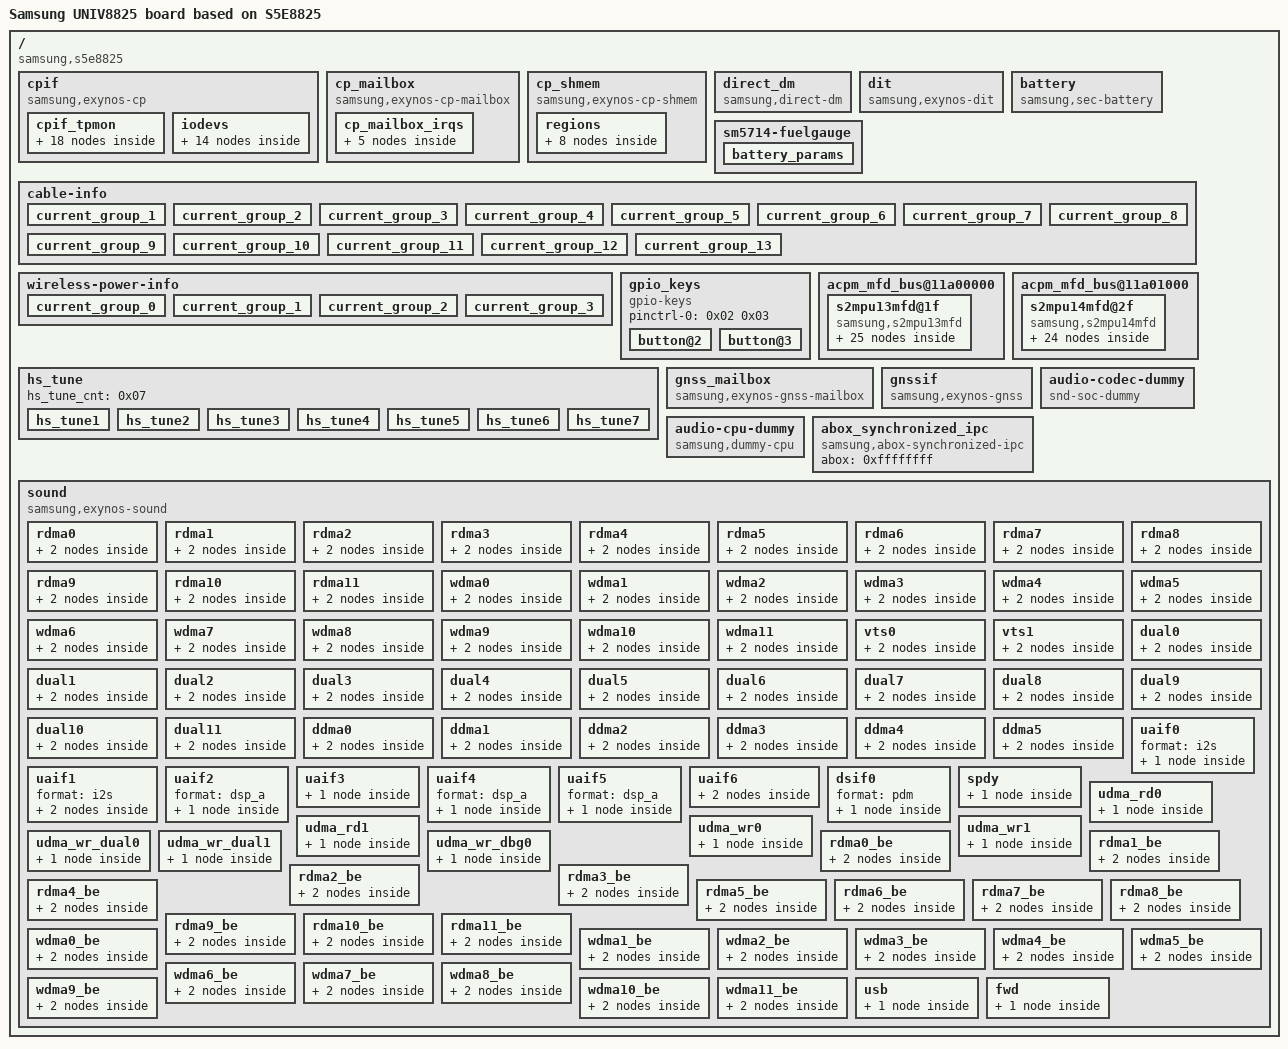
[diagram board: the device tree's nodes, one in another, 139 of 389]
/dts-v1/;

/ {
	compatible = "samsung,s5e8825\0samsung,UNIV8825";
	board_id = <0x01>;
	board_rev = <0x00>;

	fragment@modemif {
		target-path = "/";

		__overlay__ {
			#address-cells = <0x02>;
			#size-cells = <0x01>;

			cpif {
				compatible = "samsung,exynos-cp";
				status = "okay";
				interrupt-parent = <0xffffffff>;
				interrupts = <0x00 0x143 0x04 0x00 0x144 0x04>;
				interrupt-names = "RESET_REQ\0CP_ACTIVE";
				ap2cp_cfg_addr = <0x14020000>;
				mif,name = "s5308ap";
				mif,cp_num = <0x00>;
				mif,modem_type = <0x00>;
				mif,protocol = <0x01>;
				mif,ipc_version = <0x32>;
				mif,link_type = <0x00>;
				mif,link_name = "shmem";
				mif,link_attrs = <0x7c8>;
				mif,interrupt_types = <0x00>;
				mif,capability_check = <0x01>;
				mif,int_ap2cp_msg = <0x00>;
				mif,int_ap2cp_wakeup = <0x01>;
				mif,int_ap2cp_status = <0x02>;
				mif,int_ap2cp_active = <0x03>;
				mif,int_ap2cp_lcd_status = <0x04>;
				mif,int_ap2cp_llc_status = <0x05>;
				mif,int_ap2cp_uart_noti = <0x0f>;
				mif,irq_cp2ap_msg = <0x00>;
				mif,irq_cp2ap_status = <0x02>;
				mif,irq_cp2ap_active = <0x03>;
				mif,irq_cp2ap_llc_status = <0x05>;
				mif,irq_cp2ap_wakelock = <0x08>;
				mif,irq_cp2ap_ratmode = <0x09>;
				legacy_fmt_head_tail_offset = <0x10>;
				legacy_fmt_buffer_offset = <0x1000>;
				legacy_fmt_txq_size = <0x1000>;
				legacy_fmt_rxq_size = <0x1000>;
				legacy_raw_head_tail_offset = <0x20>;
				legacy_raw_buffer_offset = <0x3000>;
				legacy_raw_txq_size = <0x1fd000>;
				legacy_raw_rxq_size = <0x200000>;
				legacy_raw_rx_buffer_cached = <0x00>;
				legacy_raw_qos_head_tail_offset = <0x30>;
				legacy_raw_qos_buffer_offset = <0x400000>;
				legacy_raw_qos_txq_size = <0x100000>;
				legacy_raw_qos_rxq_size = <0x100000>;
				offset_cmsg_offset = <0x60>;
				offset_srinfo_offset = <0x64>;
				offset_clk_table_offset = <0x68>;
				offset_buff_desc_offset = <0x6c>;
				offset_capability_offset = <0x70>;
				cmsg_offset = <0xc0>;
				srinfo_offset = <0x300>;
				srinfo_size = <0x800>;
				clk_table_offset = <0x200>;
				buff_desc_offset = <0xc00>;
				capability_offset = <0xa0>;
				ap_capability_0 = <0x00>;
				ap_capability_1 = <0x00>;
				ap2cp_msg = <0x03 0x00>;
				cp2ap_msg = <0x03 0x04>;
				ap2cp_united_status = <0x03 0x08>;
				cp2ap_united_status = <0x03 0x0c>;
				ap2cp_llc_status = <0x03 0x10>;
				cp2ap_llc_status = <0x03 0x14>;
				ap2cp_kerneltime_sec = <0x03 0x38>;
				ap2cp_kerneltime_usec = <0x03 0x3c>;
				sbi_lcd_status_mask = <0x01>;
				sbi_lcd_status_pos = <0x1b>;
				sbi_crash_type_mask = <0x0f>;
				sbi_crash_type_pos = <0x17>;
				sbi_ext_backtrace_mask = <0x01>;
				sbi_ext_backtrace_pos = <0x11>;
				sbi_uart_noti_mask = <0x01>;
				sbi_uart_noti_pos = <0x10>;
				sbi_ds_det_mask = <0x03>;
				sbi_ds_det_pos = <0x0e>;
				sbi_sys_rev_mask = <0xff>;
				sbi_sys_rev_pos = <0x06>;
				sbi_pda_active_mask = <0x01>;
				sbi_pda_active_pos = <0x05>;
				sbi_ap_status_mask = <0x0f>;
				sbi_ap_status_pos = <0x01>;
				sbi_cp_rat_mode_mask = <0x3f>;
				sbi_cp_rat_mode_pos = <0x1a>;
				sbi_cp_evs_mode_mask = <0x01>;
				sbi_cp_evs_mode_pos = <0x07>;
				sbi_cp2ap_wakelock_mask = <0x01>;
				sbi_cp2ap_wakelock_pos = <0x06>;
				sbi_lte_active_mask = <0x01>;
				sbi_lte_active_pos = <0x05>;
				sbi_cp_status_mask = <0x0f>;
				sbi_cp_status_pos = <0x01>;
				sbi_ap_llc_return_mask = <0x0f>;
				sbi_ap_llc_return_pos = <0x09>;
				sbi_ap_llc_alloc_mask = <0x01>;
				sbi_ap_llc_alloc_pos = <0x08>;
				sbi_ap_llc_way_mask = <0xff>;
				sbi_ap_llc_way_pos = <0x00>;
				sbi_cp_llc_return_mask = <0x0f>;
				sbi_cp_llc_return_pos = <0x09>;
				sbi_cp_llc_alloc_mask = <0x01>;
				sbi_cp_llc_alloc_pos = <0x08>;
				sbi_cp_llc_way_mask = <0xff>;
				sbi_cp_llc_way_pos = <0x00>;
				cp_btl_node_name = "ramdump_memshare";
				pktproc_use_36bit_addr = <0x00>;
				pktproc_cp_base = <0x00 0x50800000>;
				pktproc_dl_support = <0x01>;
				pktproc_dl_version = <0x02>;
				pktproc_dl_info_rgn_offset = <0x00>;
				pktproc_dl_info_rgn_size = <0x1000>;
				pktproc_dl_desc_rgn_offset = <0x2000>;
				pktproc_dl_desc_rgn_size = <0xfe000>;
				pktproc_dl_buff_rgn_offset = <0x200000>;
				pktproc_dl_buff_rgn_size = <0x1a00000>;
				pktproc_dl_info_rgn_cached = <0x00>;
				pktproc_dl_desc_rgn_cached = <0x00>;
				pktproc_dl_buff_rgn_cached = <0x00>;
				pktproc_dl_desc_mode = <0x01>;
				pktproc_dl_num_queue = <0x01>;
				pktproc_dl_use_exclusive_irq = <0x01>;
				pktproc_dl_exclusive_irq_idx = <0x01 0x02 0x03 0x04>;
				pktproc_dl_use_netrx_mng = <0x00>;
				pktproc_dl_netrx_capacity = <0x1388>;
				pktproc_dl_use_napi = <0x01>;
				pktproc_dl_use_hw_iocc = <0x00>;
				pktproc_dl_max_packet_size = <0xc00>;
				pktproc_dl_use_dedicated_baaw = <0x00>;
				pktproc_ul_support = <0x01>;
				pktproc_ul_info_rgn_offset = <0x1000>;
				pktproc_ul_info_rgn_size = <0x1000>;
				pktproc_ul_desc_rgn_offset = <0x100000>;
				pktproc_ul_desc_rgn_size = <0x100000>;
				pktproc_ul_buff_rgn_offset = <0x1c00000>;
				pktproc_ul_buff_rgn_size = <0x400000>;
				pktproc_ul_padding_required = <0x01>;
				pktproc_ul_num_queue = <0x02>;
				pktproc_ul_max_packet_size = <0x800>;
				pktproc_ul_hiprio_ack_only = <0x01>;
				pktproc_ul_info_rgn_cached = <0x00>;
				pktproc_ul_desc_rgn_cached = <0x00>;
				pktproc_ul_buff_rgn_cached = <0x00>;
				pktproc_ul_use_hw_iocc = <0x00>;
				devfreq_use_dfs_max_freq = <0x00>;

				cpif_tpmon {
					trigger_msec_min = <0x1f4>;
					trigger_msec_max = <0x5dc>;
					monitor_interval_msec = <0x3e8>;
					monitor_hold_msec = <0xbb8>;
					monitor_stop_mbps = <0x0f>;
					boost_hold_msec = <0x1770>;

					tpmon_rps {
						boost_name = "RPS";
						target = <0x00>;
						extra_idx = <0x00>;
						level = <0x13 0x80>;

						boost0 {
							enable = <0x01>;
							measure = <0x00>;
							proto = <0x00>;
							boost_threshold = <0x12c>;
							unboost_threshold_mbps = <0x78>;
						};
					};

					tpmon_gro_flush_time {
						boost_name = "GRO";
						target = <0x01>;
						extra_idx = <0x00>;
						level = <0x1e8480 0x1e8480 0x1e8480>;

						boost0 {
							enable = <0x01>;
							measure = <0x00>;
							proto = <0x00>;
							boost_threshold = <0x64 0xc8>;
							unboost_threshold_mbps = <0x32 0x78>;
						};
					};

					tpmon_mif {
						boost_name = "MIF";
						target = <0x02>;
						extra_idx = <0x00>;
						level = <0x00 0xf78f0>;

						boost0 {
							enable = <0x01>;
							measure = <0x00>;
							proto = <0x01>;
							boost_threshold = <0x2bc>;
							unboost_threshold_mbps = <0x12c>;
						};
					};

					tpmon_cpu_cl0 {
						boost_name = "CL0";
						target = <0x09>;
						extra_idx = <0x00>;
						level = <0x00 0x104410 0x123fe0>;

						boost0 {
							enable = <0x00>;
							measure = <0x00>;
							proto = <0x01>;
							boost_threshold = <0x64 0x12c>;
							unboost_threshold_mbps = <0x28 0x78>;
						};
					};

					tpmon_cpu_cl1 {
						boost_name = "CL1";
						target = <0x0a>;
						extra_idx = <0x06>;
						level = <0x00 0xb8150 0x1174c0 0x1702a0>;

						boost0 {
							enable = <0x00>;
							measure = <0x00>;
							proto = <0x01>;
							boost_threshold = <0x1f4 0x2bc 0x5dc>;
							unboost_threshold_mbps = <0xc8 0x12c 0x258>;
						};
					};

					tpmon_irq_dit {
						boost_name = "IRQ_DIT";
						target = <0x06>;
						extra_idx = <0x00>;
						level = <0x05 0x06>;

						boost0 {
							enable = <0x01>;
							measure = <0x00>;
							proto = <0x00>;
							boost_threshold = <0x7d0>;
							unboost_threshold_mbps = <0x320>;
						};

						boost1 {
							enable = <0x01>;
							measure = <0x02>;
							proto = <0x00>;
							boost_threshold = <0x1770>;
							unboost_threshold_mbps = <0x7d0>;
						};

						boost2 {
							enable = <0x01>;
							measure = <0x03>;
							proto = <0x00>;
							boost_threshold = <0x1b58>;
							unboost_threshold_mbps = <0x7d0>;
						};
					};

					tpmon_int_freq {
						boost_name = "INT";
						target = <0x07>;
						extra_idx = <0x00>;
						level = <0x00 0x61a80 0x82208>;

						boost0 {
							enable = <0x01>;
							measure = <0x00>;
							proto = <0x00>;
							boost_threshold = <0x7d0 0xbb8>;
							unboost_threshold_mbps = <0x320 0x4b0>;
						};
					};

					tpmon_bts_dit {
						boost_name = "BTS_DIT";
						target = <0x08>;
						extra_idx = <0x00>;
						level = <0x00 0x01>;

						boost0 {
							enable = <0x01>;
							measure = <0x03>;
							proto = <0x00>;
							boost_threshold = <0xfa0>;
							unboost_threshold_mbps = <0x12c>;
						};
					};
				};

				iodevs {

					io_device_0 {
						iod,name = "umts_ipc";
						iod,ch = <0xf5>;
						iod,format = <0x00>;
						iod,io_type = <0x01>;
						iod,link_type = <0x00>;
						iod,attrs = <0x2000>;
						iod,ch_count = <0x02>;
					};

					io_device_1 {
						iod,name = "umts_rfs0";
						iod,ch = <0x29>;
						iod,format = <0x01>;
						iod,io_type = <0x01>;
						iod,link_type = <0x00>;
						iod,attrs = <0x00>;
					};

					io_device_2 {
						iod,name = "umts_router";
						iod,ch = <0x15>;
						iod,format = <0x01>;
						iod,io_type = <0x01>;
						iod,link_type = <0x00>;
						iod,attrs = <0x00>;
					};

					io_device_3 {
						iod,name = "umts_dm0";
						iod,ch = <0x51>;
						iod,format = <0x01>;
						iod,io_type = <0x01>;
						iod,link_type = <0x00>;
						iod,attrs = <0x00>;
					};

					io_device_4 {
						iod,name = "umts_loopback";
						iod,ch = <0x52>;
						iod,format = <0x01>;
						iod,io_type = <0x01>;
						iod,link_type = <0x00>;
						iod,attrs = <0x00>;
					};

					io_device_5 {
						iod,name = "rmnet";
						iod,ch = <0x01>;
						iod,format = <0x01>;
						iod,io_type = <0x02>;
						iod,link_type = <0x00>;
						iod,attrs = <0x2000>;
						iod,ch_count = <0x08>;
					};

					io_device_6 {
						iod,name = "multipdp";
						iod,ch = <0x00>;
						iod,format = <0x03>;
						iod,io_type = <0x03>;
						iod,link_type = <0x00>;
						iod,attrs = <0x00>;
					};

					io_device_7 {
						iod,name = "umts_boot0";
						iod,ch = <0xf1>;
						iod,format = <0x04>;
						iod,io_type = <0x00>;
						iod,link_type = <0x00>;
						iod,attrs = <0x200>;
					};

					io_device_8 {
						iod,name = "umts_rcs0";
						iod,ch = <0x5b>;
						iod,format = <0x00>;
						iod,io_type = <0x01>;
						iod,link_type = <0x00>;
						iod,attrs = <0x00>;
					};

					io_device_9 {
						iod,name = "umts_rcs1";
						iod,ch = <0x5c>;
						iod,format = <0x01>;
						iod,io_type = <0x01>;
						iod,link_type = <0x00>;
						iod,attrs = <0x00>;
					};

					io_device_10 {
						iod,name = "umts_wfc0";
						iod,ch = <0x5d>;
						iod,format = <0x00>;
						iod,io_type = <0x01>;
						iod,link_type = <0x00>;
						iod,attrs = <0x00>;
					};

					io_device_11 {
						iod,name = "umts_wfc1";
						iod,ch = <0x5e>;
						iod,format = <0x01>;
						iod,io_type = <0x01>;
						iod,link_type = <0x00>;
						iod,attrs = <0x00>;
					};

					io_device_12 {
						iod,name = "umts_embms";
						iod,ch = <0x1e>;
						iod,format = <0x01>;
						iod,io_type = <0x02>;
						iod,link_type = <0x00>;
						iod,attrs = <0x2000>;
						iod,ch_count = <0x02>;
					};

					io_device_13 {
						iod,name = "umts_atc0";
						iod,ch = <0x17>;
						iod,format = <0x01>;
						iod,io_type = <0x01>;
						iod,link_type = <0x00>;
						iod,attrs = <0x00>;
					};
				};
			};

			cp_mailbox {
				compatible = "samsung,exynos-cp-mailbox";
				reg = <0x00 0x11920000 0x200>;
				num_shared_reg = <0x0a>;
				shared_reg_offset = <0x100>;
				use_sw_reset_reg = <0x00>;
				interrupt-parent = <0xffffffff>;
				interrupts = <0x00 0x1f 0x04 0x00 0x20 0x04 0x00 0x21 0x04 0x00 0x22 0x04 0x00 0x23 0x04>;

				cp_mailbox_irqs {

					cp_irq_0 {
						cp_irq,enable = <0x01>;
						cp_irq,idx = <0x00>;
						cp_irq,name = "cp_mbox_irq_0";
						cp_irq,sfr = <0x00 0x10 0x14 0x00>;
						cp_irq,affinity = <0x02>;
					};

					cp_irq_1 {
						cp_irq,enable = <0x01>;
						cp_irq,idx = <0x01>;
						cp_irq,name = "cp_mbox_irq_1";
						cp_irq,sfr = <0x28 0x00 0x14 0x00>;
						cp_irq,affinity = <0x03>;
					};

					cp_irq_2 {
						cp_irq,enable = <0x00>;
						cp_irq,idx = <0x02>;
						cp_irq,name = "cp_mbox_irq_2";
						cp_irq,sfr = <0x3c 0x00 0x14 0x00>;
						cp_irq,affinity = <0x02>;
					};

					cp_irq_3 {
						cp_irq,enable = <0x00>;
						cp_irq,idx = <0x03>;
						cp_irq,name = "cp_mbox_irq_3";
						cp_irq,sfr = <0x50 0x00 0x14 0x00>;
						cp_irq,affinity = <0x01>;
					};

					cp_irq_4 {
						cp_irq,enable = <0x01>;
						cp_irq,idx = <0x04>;
						cp_irq,name = "cp_mbox_irq_4";
						cp_irq,sfr = <0x64 0x00 0x14 0x00>;
						cp_irq,affinity = <0x02>;
					};
				};
			};

			cp_shmem {
				compatible = "samsung,exynos-cp-shmem";
				memory-region = <0xffffffff 0x01>;
				cp_num = <0x00>;
				use_mem_map_on_cp = <0x01>;

				regions {

					cp {
						region,name = "CP";
						region,index = <0x00>;
						region,rmem = <0x00>;
						region,offset = <0x00>;
						region,size = <0xf800000>;
						region,cached = <0x00>;
					};

					vss {
						region,name = "VSS";
						region,index = <0x01>;
						region,rmem = <0x00>;
						region,offset = <0xf800000>;
						region,size = <0x800000>;
						region,cached = <0x00>;
					};

					ipc {
						region,name = "IPC";
						region,index = <0x03>;
						region,rmem = <0x01>;
						region,offset = <0x00>;
						region,size = <0x800000>;
						region,cached = <0x00>;
					};

					pktproc {
						region,name = "PKTPROC";
						region,index = <0x07>;
						region,rmem = <0x01>;
						region,offset = <0x800000>;
						region,size = <0x1c00000>;
					};

					pktproc_ul {
						region,name = "PKTPROC_UL";
						region,index = <0x08>;
						region,rmem = <0x01>;
						region,offset = <0x2400000>;
						region,size = <0x400000>;
						region,cached = <0x00>;
					};

					l2b {
						region,name = "L2B";
						region,index = <0x02>;
						region,rmem = <0x01>;
						region,offset = <0x2800000>;
						region,size = <0xf00000>;
					};

					ddm {
						region,name = "DDM";
						region,index = <0x0c>;
						region,rmem = <0x01>;
						region,offset = <0x3700000>;
						region,size = <0x400000>;
					};

					btl {
						region,name = "BTL";
						region,index = <0x05>;
						region,rmem = <0x01>;
						region,offset = <0x3b00000>;
						region,size = <0x2000000>;
						region,cached = <0x00>;
					};
				};
			};

			direct_dm {
				compatible = "samsung,direct-dm";
				version = <0x01>;
				shm_rgn_index = <0x0c>;
				hw_iocc = <0x00>;
				info_desc_rgn_cached = <0x00>;
				buff_rgn_cached = <0x00>;
				info_rgn_offset = <0x00>;
				info_rgn_size = <0x100>;
				desc_rgn_offset = <0x100>;
				desc_rgn_size = <0x7f00>;
				buff_rgn_offset = <0x8000>;
				max_packet_size = <0x8000>;
				usb_req_num = <0x80>;
				irq_index = <0x04>;
				use_rx_task = <0x00>;
				use_rx_timer = <0x01>;
				rx_timer_period_msec = <0x3e8>;
			};
		};
	};

	fragment@0 {
		target = <0xffffffff>;

		__overlay__ {
			#address-cells = <0x02>;
			#size-cells = <0x01>;

			cp_rmem1 {
				compatible = "exynos,modem_if";
				reg = <0x08 0x90000000 0x5b00000>;
				rmem_index = <0x01>;
				phandle = <0x01>;
			};
		};
	};

	fragment@dit {
		target-path = "/";

		__overlay__ {
			#address-cells = <0x02>;
			#size-cells = <0x01>;

			dit {
				compatible = "samsung,exynos-dit";
				status = "okay";
				interrupt-parent = <0xffffffff>;
				interrupts = <0x00 0x1dd 0x04 0x00 0x1dc 0x04 0x00 0x1db 0x04 0x00 0x1de 0x04 0x00 0x1df 0x04>;
				interrupt-names = "DIT-RxDst0\0DIT-RxDst1\0DIT-RxDst2\0DIT-Tx\0DIT-Err";
				reg = <0x00 0x12950000 0x10000>;
				reg-names = "dit";
				dit_hw_capabilities = <0x00>;
				dit_use_tx = <0x01>;
				dit_use_rx = <0x01>;
				dit_use_clat = <0x00>;
				dit_use_recycling = <0x01>;
				dit_hal_support = <0x00>;
				dit_hal_enqueue_rx = <0x00>;
				dit_rx_extra_desc_ring_len = <0x800>;
				dit_irq_affinity = <0x02>;
			};
		};
	};

	fragment@battery {
		target-path = "/";

		__overlay__ {

			battery {
				status = "okay";
				compatible = "samsung,sec-battery";
				pinctrl-names = "default";
				battery,vendor = "Battery";
				battery,charger_name = "sm5714-charger";
				battery,fuelgauge_name = "sm5714-fuelgauge";
				battery,technology = <0x02>;
				battery,fgsrc_switch_name = "sm5714-fuelgauge";
				battery,batt_data_version = <0x03>;
				battery,chip_vendor = "LSI";
				battery,temp_adc_type = <0x01>;
				battery,temp_check_type = <0x03>;
				battery,usb_temp_check_type = <0x03>;
				battery,chg_temp_check_type = <0x03>;
				battery,wpc_temp_check_type = <0x03>;
				battery,dchg_temp_check_type = <0x03>;
				battery,thermal_source = <0x02>;
				battery,usb_thermal_source = <0x02>;
				battery,chg_thermal_source = <0x02>;
				battery,wpc_thermal_source = <0x02>;
				battery,dchg_thermal_source = <0x03>;
				battery,polling_time = <0x0a 0x1e 0x1e 0x1e 0xe10>;
				battery,temp_table_adc = <0x137 0x168 0x1a0 0x1e3 0x232 0x28f 0x2fb 0x379 0x409 0x48a 0x53c 0x603 0x6da 0x7ba 0x8ab 0x99b 0xa8a 0xb6a 0xc33 0xce8 0xd89 0xe04 0xe5f>;
				battery,temp_table_data = <0x384 0x352 0x320 0x2ee 0x2bc 0x28a 0x258 0x226 0x1f4 0x1c2 0x190 0x15e 0x12c 0xfa 0xc8 0x96 0x64 0x32 0x00 0xffffffce 0xffffff9c 0xffffff6a 0xffffff38>;
				battery,usb_temp_table_adc = <0x10c 0x146 0x180 0x1c5 0x214 0x270 0x2dd 0x35b 0x3e9 0x489 0x54c 0x616 0x6ee 0x7d0 0x8bb 0x9a6 0xa84 0xb61 0xc1c 0xcce 0xd67 0xdd3 0xe51>;
				battery,usb_temp_table_data = <0x384 0x352 0x320 0x2ee 0x2bc 0x28a 0x258 0x226 0x1f4 0x1c2 0x190 0x15e 0x12c 0xfa 0xc8 0x96 0x64 0x32 0x00 0xffffffce 0xffffff9c 0xffffff6a 0xffffff38>;
				battery,chg_temp_table_adc = <0xdd 0x114 0x14b 0x18e 0x1da 0x234 0x29b 0x31a 0x3a7 0x448 0x505 0x5d1 0x6af 0x799 0x889 0x97c 0xa69 0xb4f 0xc1f 0xcdb 0xd76 0xdf0 0xe75>;
				battery,chg_temp_table_data = <0x384 0x352 0x320 0x2ee 0x2bc 0x28a 0x258 0x226 0x1f4 0x1c2 0x190 0x15e 0x12c 0xfa 0xc8 0x96 0x64 0x32 0x00 0xffffffce 0xffffff9c 0xffffff6a 0xffffff38>;
				battery,wpc_temp_table_adc = <0x137 0x168 0x1a0 0x1e3 0x232 0x28f 0x2fb 0x379 0x409 0x48a 0x53c 0x603 0x6da 0x7ba 0x8ab 0x99b 0xa8a 0xb6a 0xc33 0xce8 0xd89 0xe04 0xe5f>;
				battery,wpc_temp_table_data = <0x384 0x352 0x320 0x2ee 0x2bc 0x28a 0x258 0x226 0x1f4 0x1c2 0x190 0x15e 0x12c 0xfa 0xc8 0x96 0x64 0x32 0x00 0xffffffce 0xffffff9c 0xffffff6a 0xffffff38>;
				battery,dchg_temp_table_adc = <0x15c3c 0x1b7e0 0x21384 0x2817c 0x301c8 0x39d92 0x454da 0x527a0 0x61f0e 0x731fa 0x86064 0x9c5ca 0xb3d84 0xcd9e6 0xe7648 0x1024fe 0x11c160 0x134b6e 0x14b9fe 0x15fabc 0x170da8 0x17f2c2 0x18b334>;
				battery,dchg_temp_table_data = <0x384 0x352 0x320 0x2ee 0x2bc 0x28a 0x258 0x226 0x1f4 0x1c2 0x190 0x15e 0x12c 0xfa 0xc8 0x96 0x64 0x32 0x00 0xffffffce 0xffffff9c 0xffffff6a 0xffffff38>;
				battery,wireless_cc_cv = <0x55>;
				battery,wpc_cc_cv_vout = <0x157c>;
				battery,wpc_cv_call_vout = <0x1388>;
				battery,wpc_cc_call_vout = <0x1388>;
				battery,hv_vout_wa = <0x41>;
				battery,adc_check_count = <0x05>;
				battery,cable_check_type = <0x04>;
				battery,cable_source_type = <0x01>;
				battery,polling_type = <0x01>;
				battery,monitor_initial_count = <0x00>;
				battery,battery_check_type = <0x00>;
				battery,check_count = <0x00>;
				battery,check_adc_max = <0x5a0>;
				battery,check_adc_min = <0x00>;
				battery,ovp_uvlo_check_type = <0x03>;
				battery,temp_check_count = <0x01>;
				battery,overheatlimit_threshold = <0x2bc>;
				battery,overheatlimit_recovery = <0x2a8>;
				battery,wire_warm_overheat_thresh = <0x1f4>;
				battery,wire_normal_warm_thresh = <0x19a>;
				battery,wire_cool1_normal_thresh = <0xb4>;
				battery,wire_cool2_cool1_thresh = <0x96>;
				battery,wire_cool3_cool2_thresh = <0x32>;
				battery,wire_cold_cool3_thresh = <0x00>;
				battery,wireless_warm_overheat_thresh = <0x1c2>;
				battery,wireless_normal_warm_thresh = <0x19a>;
				battery,wireless_cool1_normal_thresh = <0xb4>;
				battery,wireless_cool2_cool1_thresh = <0x96>;
				battery,wireless_cool3_cool2_thresh = <0x32>;
				battery,wireless_cold_cool3_thresh = <0x00>;
				battery,wire_warm_current = <0x625>;
				battery,wire_cool1_current = <0xc4a>;
				battery,wire_cool2_current = <0x418>;
				battery,wire_cool3_current = <0x1b5>;
				battery,wireless_warm_current = <0x418>;
				battery,wireless_cool1_current = <0xc4a>;
				battery,wireless_cool2_current = <0x418>;
				battery,wireless_cool3_current = <0x1b5>;
				battery,tx_high_threshold = <0x1c2>;
				battery,tx_high_recovery = <0x190>;
				battery,tx_low_threshold = <0x00>;
				battery,tx_low_recovery = <0x32>;
				battery,full_check_type = <0x02>;
				battery,full_check_type_2nd = <0x02>;
				battery,full_check_count = <0x01>;
				battery,chg_gpio_full_check = <0x00>;
				battery,chg_polarity_full_check = <0x01>;
				battery,chg_high_temp = <0x1d6>;
				battery,chg_high_temp_recovery = <0x1c2>;
				battery,dchg_high_temp = <0x208>;
				battery,dchg_high_temp_recovery = <0x1cc>;
				battery,dchg_high_batt_temp = <0x190>;
				battery,dchg_high_batt_temp_recovery = <0x17c>;
				battery,chg_input_limit_current = <0x3e8>;
				battery,chg_charging_limit_current = <0x76c>;
				battery,dchg_input_limit_current = <0x3e8>;
				battery,dchg_charging_limit_current = <0x7d0>;
				battery,charging_limit_by_tx_check = <0x01>;
				battery,charging_limit_current_by_tx = <0x4b0>;
				battery,wpc_temp_control_source = <0x01>;
				battery,wpc_high_temp = <0x190>;
				battery,wpc_high_temp_recovery = <0x17c>;
				battery,wpc_input_limit_current = <0x258>;
				battery,wpc_charging_limit_current = <0x3e8>;
				battery,wpc_temp_lcd_on_control_source = <0x01>;
				battery,wpc_lcd_on_high_temp = <0x190>;
				battery,wpc_lcd_on_high_temp_rec = <0x17c>;
				battery,wpc_lcd_on_input_limit_current = <0x1c2>;
				battery,wpc_store_high_temp = <0x168>;
				battery,wpc_store_high_temp_recovery = <0x154>;
				battery,wpc_store_lcd_on_high_temp = <0x168>;
				battery,wpc_store_lcd_on_high_temp_rec = <0x12c>;
				battery,wpc_store_lcd_on_charging_limit_current = <0x190>;
				battery,sleep_mode_limit_current = <0x320>;
				battery,wc_full_input_limit_current = <0x64>;
				battery,mix_high_temp = <0x1a4>;
				battery,mix_high_chg_temp = <0x1f4>;
				battery,mix_high_dc_temp = <0x244>;
				battery,mix_high_temp_recovery = <0x186>;
				battery,full_condition_type = <0x09>;
				battery,full_condition_soc = <0x5d>;
				battery,full_condition_vcell = <0x10ea>;
				battery,recharge_check_count = <0x01>;
				battery,recharge_condition_type = <0x04>;
				battery,recharge_condition_soc = <0x62>;
				battery,recharge_condition_vcell = <0x10d6>;
				battery,charging_total_time = <0x3840>;
				battery,hv_charging_total_time = <0x2a30>;
				battery,normal_charging_total_time = <0x4650>;
				battery,usb_charging_total_time = <0x8ca0>;
				battery,recharging_total_time = <0x1518>;
				battery,charging_reset_time = <0x00>;
				battery,chg_float_voltage = <0x111c>;
				battery,chg_ocp_current = <0x1838>;
				battery,chg_ocp_dtc = <0x64>;
				battery,swelling_drop_float_voltage = <0x1036>;
				battery,swelling_high_rechg_voltage = <0xfa0>;
				battery,swelling_low_rechg_voltage = <0xfa0>;
				battery,wa_float_voltage = <0xfd2>;
				battery,siop_event_check_type = <0x01>;
				battery,siop_call_cv_current = <0x12c>;
				battery,siop_call_cc_current = <0x12c>;
				battery,siop_input_limit_current = <0x4b0>;
				battery,siop_charging_limit_current = <0x3e8>;
				battery,siop_hv_input_limit_current = <0x2bc>;
				battery,siop_hv_charging_limit_current = <0x3e8>;
				battery,siop_apdo_input_limit_current = <0x4b0>;
				battery,siop_apdo_charging_limit_current = <0x7d0>;
				battery,siop_wireless_input_limit_current = <0x258>;
				battery,siop_wireless_charging_limit_current = <0x352>;
				battery,siop_hv_wireless_input_limit_current = <0x2bc>;
				battery,siop_hv_wireless_charging_limit_current = <0x352>;
				battery,siop_store_hv_wireless_input_limit_current = <0x1c2>;
				battery,store_mode_buckoff;
				battery,ttf_hv_charge_current = <0xbb8>;
				battery,ttf_hv_wireless_charge_current = <0x5dc>;
				battery,ttf_wireless_charge_current = <0x384>;
				battery,ttf_dc25_charge_current = <0x1068>;
				battery,ttf_dc45_charge_current = <0x1770>;
				battery,rp_current_rp1 = <0x1f4>;
				battery,rp_current_rp2 = <0x5dc>;
				battery,rp_current_rp3 = <0xbb8>;
				battery,rp_current_rdu_rp3 = <0x834>;
				battery,rp_current_abnormal_rp3 = <0x708>;
				battery,pd_charging_charge_power = <0x3a98>;
				battery,max_charging_current = <0xc4e>;
				battery,max_charging_charge_power = <0x61a8>;
				battery,battery_full_capacity = <0x1194>;
				battery,age_data = <0x00 0x111c 0x10d6 0x10ea 0x5d 0x12c 0x1108 0x10c2 0x10d6 0x5c 0x190 0x10f4 0x10ae 0x10c2 0x5b 0x2bc 0x10e0 0x109a 0x10ae 0x5a 0x3e8 0x10ae 0x1068 0x107c 0x59>;
				battery,health_condition = <0x384 0x4b 0x4b0 0x41 0x5dc 0x37>;
				battery,step_charging_type = <0x00>;
				battery,dc_step_chg_type = <0x6b>;
				battery,dc_step_chg_charge_power = <0x55f0>;
				battery,dc_step_chg_step = <0x03>;
				battery,dc_step_chg_step_2nd = <0x00>;
				battery,dc_step_chg_cond_vol = <0x101d 0x109a 0x111c>;
				battery,dc_step_chg_cond_iin = <0x7ee 0x721 0x00>;
				battery,dc_step_chg_val_vfloat = <0x101d 0x109a 0x111c>;
				battery,dc_step_chg_val_iout = <0x14aa 0xffa 0xe56>;
				battery,dc_step_chg_cond_soc = <0x14 0x32 0x64 0x14 0x32 0x64 0x14 0x32 0x64 0x14 0x32 0x64 0x14 0x32 0x64>;
				battery,pre_afc_input_current = <0x1f4>;
				battery,pre_afc_work_delay = <0x2710>;
				battery,prepare_ta_delay = <0x00>;
				battery,max_input_voltage = <0x2328>;
				battery,max_input_current = <0xbb8>;
				battery,enable_sysovlo_irq;
				battery,enable_noise_wa;
				battery,dis_auto_shipmode_temp_ctrl;
				battery,standard_curr = <0xc4e>;
				battery,expired_time = <0x2a30>;
				battery,recharging_expired_time = <0x1518>;
				battery,cisd_max_voltage_thr = <0x114e>;
				battery,cisd_alg_index = <0x08>;
				battery,ignore_cisd_index = <0x00 0x280>;
				battery,ignore_cisd_index_d = <0x00 0x50>;
				battery,tx_stop_capacity = <0x1e>;
				battery,tx_minduty_default = <0x14>;
				battery,tx_minduty_5V = <0x32>;
				battery,tx_uno_iout = <0x5dc>;
				battery,tx_mfc_iout_gear = <0x5dc>;
				battery,tx_mfc_iout_phone = <0x44c>;
				battery,tx_mfc_iout_phone_5v = <0x12c>;
				battery,tx_mfc_iout_lcd_on = <0x384>;
				#io-channel-cells = <0x05>;
				phandle = <0x15>;
			};

			sm5714-fuelgauge {
				status = "okay";
				fuelgauge,fuel_alert_soc = <0x01>;
				fuelgauge,capacity_max = <0x3e8>;
				fuelgauge,capacity_max_margin = <0x12c>;
				fuelgauge,capacity_min = <0x00>;
				fuelgauge,capacity_calculation_type = <0x1f>;
				fuelgauge,using_temp_compensation;
				fuelgauge,low_temp_limit = <0x64>;
				fuelgauge,using_hw_vempty;
				fuelgauge,sw_v_empty_voltage = <0xc80>;
				fuelgauge,sw_v_empty_voltage_cisd = <0xc1c>;
				fuelgauge,sw_v_empty_recover_voltage = <0xd98>;
				fuelgauge,capacity = <0x1388>;
				phandle = <0x16>;

				battery_params {
					battery,id = <0x00>;
					battery0,battery_type = <0x1130 0x2406>;
					battery0,battery_table0 = <0x1400 0x1b49 0x1c6e 0x1d41 0x1d71 0x1d80 0x1d94 0x1dda 0x1e17 0x1e3b 0x1e53 0x1e71 0x1e97 0x1ee7 0x1f14 0x1f58 0x1fb5 0x1fec 0x2025 0x2095 0x20e3 0x2122 0x2226 0x2400>;
					battery0,battery_table1 = <0x00 0x99 0x24c 0x480 0x599 0x74c 0xccc 0x1266 0x1ab3 0x204c 0x25cc 0x2b66 0x30e6 0x3933 0x3c00 0x3ecc 0x4466 0x49e6 0x4cb3 0x4f80 0x5500 0x57cc 0x6400 0x6419>;
					battery0,battery_table2 = <0x4b4b 0x4444 0x4040 0x3e3e 0x3c3c 0x3b3b 0x3838 0x3737 0x3535 0x3434 0x3434 0x3333 0x3333 0x3333 0x3333 0x3232>;
					battery0,rs_value = <0x48 0x48 0x3800 0x10a 0x599 0x599 0x50>;
					battery0,v_alarm = <0xc1c 0xc8>;
					battery0,topoff = <0x1f4>;
					battery0,i_cal = <0x01 0x00 0x800 0x800 0x00 0x00 0x7e8 0x818>;
					battery0,v_cal = <0x01 0x00 0x00 0x01 0x00 0x00 0x00>;
					battery0,temp_std = <0x19>;
					battery0,tem_poff = <0xd48 0x32 0xcb2 0x32>;
					battery0,aux_ctrl = <0x322 0x5800>;
					battery0,data_ver = <0x03>;
					battery0,v_max_table = <0x2226 0x2203 0x21e0 0x21bc 0x2165>;
					battery0,q_max_table = <0x2406 0x235f 0x22b9 0x2212 0x2071>;
				};
			};

			cable-info {
				default_input_current = <0x708>;
				default_charging_current = <0x834>;
				full_check_current_1st = <0x28f>;
				full_check_current_2nd = <0xda>;
				phandle = <0x17>;

				current_group_1 {
					cable_number = <0x02 0x13 0x15 0x16 0x17 0x1e>;
					input_current = <0x1f4>;
					charging_current = <0x1f4>;
				};

				current_group_2 {
					cable_number = <0x19 0x1f>;
					input_current = <0x3e8>;
					charging_current = <0x3e8>;
				};

				current_group_3 {
					cable_number = <0x05 0x20>;
					input_current = <0x5dc>;
					charging_current = <0x5dc>;
				};

				current_group_4 {
					cable_number = <0x06 0x07 0x08>;
					input_current = <0x672>;
					charging_current = <0xc4e>;
				};

				current_group_5 {
					cable_number = <0x09>;
					input_current = <0x672>;
					charging_current = <0xc4e>;
				};

				current_group_6 {
					cable_number = <0x0a 0x0c 0x0f 0x1b 0x21 0x23>;
					input_current = <0x320>;
					charging_current = <0xc4e>;
				};

				current_group_7 {
					cable_number = <0x0d>;
					input_current = <0x2bc>;
					charging_current = <0xc4e>;
				};

				current_group_8 {
					cable_number = <0x18>;
					input_current = <0x3e8>;
					charging_current = <0x1c2>;
				};

				current_group_9 {
					cable_number = <0x1a>;
					input_current = <0x7d0>;
					charging_current = <0x708>;
				};

				current_group_10 {
					cable_number = <0x0b 0x0e 0x10 0x1c>;
					input_current = <0x2ee>;
					charging_current = <0xc4e>;
				};

				current_group_11 {
					cable_number = <0x1d 0x24 0x25>;
					input_current = <0x1f4>;
					charging_current = <0x578>;
				};

				current_group_12 {
					cable_number = <0x01 0x04>;
					input_current = <0x1db>;
					charging_current = <0x226>;
				};

				current_group_13 {
					cable_number = <0x22>;
					input_current = <0x1f4>;
					charging_current = <0xc4e>;
				};
			};

			wireless-power-info {
				phandle = <0x18>;

				current_group_0 {
					wireless_power_class = <0x01>;
					vout = <0x157c>;
					input_current_limit = <0x320>;
					fast_charging_current = <0xc4e>;
					ttf_charge_current = <0x384>;
					rx_power = <0x1194>;
				};

				current_group_1 {
					wireless_power_class = <0x02>;
					vout = <0x2710>;
					input_current_limit = <0x2ee>;
					fast_charging_current = <0xc4e>;
					ttf_charge_current = <0x5dc>;
					rx_power = <0x1d4c>;
				};

				current_group_2 {
					wireless_power_class = <0x02>;
					vout = <0x2af8>;
					input_current_limit = <0x44c>;
					fast_charging_current = <0xc4e>;
					ttf_charge_current = <0x834>;
					rx_power = <0x2ee0>;
				};

				current_group_3 {
					wireless_power_class = <0x02>;
					vout = <0x2af8>;
					input_current_limit = <0x514>;
					fast_charging_current = <0xc4e>;
					ttf_charge_current = <0x8fc>;
					rx_power = <0x36b0>;
				};
			};
		};
	};

	fragment@model {
		target-path = "/";

		__overlay__ {
			#address-cells = <0x02>;
			#size-cells = <0x01>;
			model = "Samsung UNIV8825 board based on S5E8825";

			gpio_keys {
				status = "okay";
				compatible = "gpio-keys";
				pinctrl-names = "default";
				pinctrl-0 = <0x02 0x03>;

				button@2 {
					label = "gpio-keys: KEY_VOLUMEDOWN";
					linux,code = <0x72>;
					gpios = <0xffffffff 0x07 0x0f>;
				};

				button@3 {
					label = "gpio-keys: KEY_VOLUMEUP";
					linux,code = <0x73>;
					gpios = <0xffffffff 0x00 0x0f>;
				};
			};

			hs_tune {
				hs_tune_cnt = <0x07>;
				phandle = <0x13>;

				hs_tune1 {
					tune_name = "tx_pre_emp";
					tune_value = <0x03 0x03>;
				};

				hs_tune2 {
					tune_name = "tx_vref";
					tune_value = <0x0d 0x0d>;
				};

				hs_tune3 {
					tune_name = "rx_sqrx";
					tune_value = <0x07 0x07>;
				};

				hs_tune4 {
					tune_name = "utmi_clk";
					tune_value = <0x01 0x01>;
				};

				hs_tune5 {
					tune_name = "compdis";
					tune_value = <0x07 0x07>;
				};

				hs_tune6 {
					tune_name = "tx_res";
					tune_value = <0x01 0x01>;
				};

				hs_tune7 {
					tune_name = "tx_rise";
					tune_value = <0x01 0x01>;
				};
			};

			acpm_mfd_bus@11a00000 {
				status = "okay";
				#address-cells = <0x01>;
				#size-cells = <0x00>;

				s2mpu13mfd@1f {
					compatible = "samsung,s2mpu13mfd";
					acpm-ipc-channel = <0x02>;
					s2mpu13,wakeup = "enabled";
					reg = <0x1f>;
					interrupts = <0x00 0x18 0x04>;
					interrupt-parent = <0xffffffff>;
					pinctrl-names = "default";
					pinctrl-0 = <0x04 0x05>;
					gpios = <0xffffffff 0x00 0x00>;
					wtsr_en = "enabled";
					smpl_en = "enabled";
					wtsr_timer_val = <0x03>;
					smpl_timer_val = <0x04>;
					sub_smpl_en = "enabled";
					check_jigon = <0x00>;
					init_time,sec = <0x00>;
					init_time,min = <0x00>;
					init_time,hour = <0x0c>;
					init_time,mday = <0x01>;
					init_time,mon = <0x00>;
					init_time,year = <0x79>;
					init_time,wday = <0x05>;
					smpl_warn_en = <0x01>;
					sel_vgpio = <0x24 0x32 0x11 0x39 0x33 0x33 0x22 0x33 0x24 0xb1 0xc1 0xb1 0x77 0x5b 0x5e 0xcc 0x73 0x33 0xf3>;

					s2mpu13-gpadc {
						#io-channel-cells = <0x01>;
						io-channel-ranges;
						acpm-ipc-channel = <0x0a>;
						phandle = <0x19>;
					};

					s2mpu13-gpio {
						gpio-controller;
						#gpio-cells = <0x02>;
						samsung,npins = <0x05>;
						status = "okay";
						phandle = <0x1a>;
					};

					s2mpu13-keys {

						button@1 {
							label = "pmic-keys: KEY_POWER";
							linux,code = <0x74>;
							wakeup = <0x01>;
						};
					};

					regulators {

						BUCK1 {
							regulator-name = "vdd_g3d";
							regulator-min-microvolt = <0x61a80>;
							regulator-max-microvolt = <0x13d620>;
							regulator-always-on;
							regulator-ramp-delay = <0x1770>;
							regulator-initial-mode = <0x01>;
							phandle = <0x1b>;
						};

						BUCK4 {
							regulator-name = "vdd_mem_vdd2";
							regulator-min-microvolt = <0x61a80>;
							regulator-max-microvolt = <0x13d620>;
							regulator-always-on;
							regulator-ramp-delay = <0x1770>;
							regulator-initial-mode = <0x03>;
							phandle = <0x1c>;
						};

						BUCK5 {
							regulator-name = "vdd2_int";
							regulator-min-microvolt = <0x61a80>;
							regulator-max-microvolt = <0x13d620>;
							regulator-always-on;
							regulator-ramp-delay = <0x1770>;
							regulator-initial-mode = <0x01>;
							phandle = <0x1d>;
						};

						BUCK6 {
							regulator-name = "vddq_mem_vddq";
							regulator-min-microvolt = <0x61a80>;
							regulator-max-microvolt = <0x13d620>;
							regulator-always-on;
							regulator-ramp-delay = <0x1770>;
							regulator-initial-mode = <0x01>;
							phandle = <0x1e>;
						};

						BUCK8 {
							regulator-name = "vdd_lldo1";
							regulator-min-microvolt = <0x61a80>;
							regulator-max-microvolt = <0x155cc0>;
							regulator-always-on;
							regulator-ramp-delay = <0x1770>;
							regulator-initial-mode = <0x03>;
							phandle = <0x1f>;
						};

						BUCK9 {
							regulator-name = "vdd_lldo2";
							regulator-min-microvolt = <0xdbba0>;
							regulator-max-microvolt = <0x155cc0>;
							regulator-always-on;
							regulator-ramp-delay = <0x1770>;
							regulator-initial-mode = <0x03>;
							phandle = <0x20>;
						};

						BUCK10 {
							regulator-name = "vdd_mldo";
							regulator-min-microvolt = <0x1ab3f0>;
							regulator-max-microvolt = <0x20ce70>;
							regulator-always-on;
							regulator-ramp-delay = <0x1770>;
							regulator-initial-mode = <0x03>;
							phandle = <0x21>;
						};

						LDO1 {
							regulator-name = "vdd_ldo1";
							regulator-min-microvolt = <0xb1008>;
							regulator-max-microvolt = <0x13d620>;
							regulator-always-on;
							regulator-ramp-delay = <0x2ee0>;
							regulator-initial-mode = <0x03>;
							phandle = <0x22>;
						};

						LDO2 {
							regulator-name = "vdd_ldo2";
							regulator-min-microvolt = <0x186a00>;
							regulator-max-microvolt = <0x1dc130>;
							regulator-always-on;
							regulator-ramp-delay = <0x2ee0>;
							regulator-initial-mode = <0x03>;
							phandle = <0x23>;
						};

						LDO7 {
							regulator-name = "vdd_ldo7";
							regulator-min-microvolt = <0x61a80>;
							regulator-max-microvolt = <0x13d620>;
							regulator-always-on;
							regulator-ramp-delay = <0x2ee0>;
							regulator-initial-mode = <0x01>;
							phandle = <0x24>;
						};

						LDO9 {
							regulator-name = "vdd_ldo9";
							regulator-min-microvolt = <0x61a80>;
							regulator-max-microvolt = <0x13d620>;
							regulator-always-on;
							regulator-ramp-delay = <0x2ee0>;
							regulator-initial-mode = <0x01>;
							phandle = <0x25>;
						};

						LDO10 {
							regulator-name = "vdd_ldo10";
							regulator-min-microvolt = <0x61a80>;
							regulator-max-microvolt = <0x13d620>;
							regulator-always-on;
							regulator-ramp-delay = <0x2ee0>;
							regulator-initial-mode = <0x01>;
							phandle = <0x26>;
						};

						LDO11 {
							regulator-name = "vdd_ldo11";
							regulator-min-microvolt = <0xb1008>;
							regulator-max-microvolt = <0x13d620>;
							regulator-always-on;
							regulator-ramp-delay = <0x2ee0>;
							regulator-initial-mode = <0x01>;
							phandle = <0x27>;
						};

						LDO13 {
							regulator-name = "vdd_ldo13";
							regulator-min-microvolt = <0x186a00>;
							regulator-max-microvolt = <0x1dc130>;
							regulator-always-on;
							regulator-ramp-delay = <0x2ee0>;
							regulator-initial-mode = <0x01>;
							phandle = <0x28>;
						};

						LDO14 {
							regulator-name = "vdd_ldo14";
							regulator-min-microvolt = <0x186a00>;
							regulator-max-microvolt = <0x1dc130>;
							regulator-always-on;
							regulator-ramp-delay = <0x2ee0>;
							regulator-initial-mode = <0x01>;
							phandle = <0x29>;
						};

						LDO17 {
							regulator-name = "vdd_ldo17";
							regulator-min-microvolt = <0xb1008>;
							regulator-max-microvolt = <0x13d620>;
							regulator-always-on;
							regulator-ramp-delay = <0x2ee0>;
							regulator-initial-mode = <0x01>;
							phandle = <0x2a>;
						};

						LDO23 {
							regulator-name = "vdd_ldo23";
							regulator-min-microvolt = <0x186a00>;
							regulator-max-microvolt = <0x1dc130>;
							regulator-always-on;
							regulator-ramp-delay = <0x2ee0>;
							regulator-initial-mode = <0x03>;
							phandle = <0x2b>;
						};

						LDO25 {
							regulator-name = "vdd_ldo25";
							regulator-min-microvolt = <0x186a00>;
							regulator-max-microvolt = <0x1dc130>;
							regulator-always-on;
							regulator-ramp-delay = <0x2ee0>;
							regulator-initial-mode = <0x03>;
							phandle = <0x2c>;
						};

						LDO26 {
							regulator-name = "vdd_ldo26";
							regulator-min-microvolt = <0x186a00>;
							regulator-max-microvolt = <0x1dc130>;
							regulator-always-on;
							regulator-ramp-delay = <0x2ee0>;
							regulator-initial-mode = <0x03>;
							phandle = <0x0a>;
						};

						LDO27 {
							regulator-name = "vdd_ldo27";
							regulator-min-microvolt = <0x186a00>;
							regulator-max-microvolt = <0x1dc130>;
							regulator-ramp-delay = <0x2ee0>;
							regulator-initial-mode = <0x03>;
							phandle = <0x0d>;
						};
					};
				};
			};

			acpm_mfd_bus@11a01000 {
				status = "okay";
				#address-cells = <0x01>;
				#size-cells = <0x00>;

				s2mpu14mfd@2f {
					compatible = "samsung,s2mpu14mfd";
					acpm-ipc-channel = <0x02>;
					s2mpu14,wakeup = "enabled";
					reg = <0x2f>;
					wtsr_en = <0x01>;
					sel_vgpio = <0x0a 0x68 0xb1 0x33 0x03 0x68 0xa1 0x21 0x73 0x33 0x53 0x56 0xc5 0x7c 0x77 0x33 0x33 0x33 0x03>;

					s2mpu14-gpio {
						gpio-controller;
						#gpio-cells = <0x02>;
						samsung,npins = <0x04>;
						status = "okay";
						phandle = <0x2d>;
					};

					regulators {

						BUCK1 {
							regulator-name = "vdd_npu";
							regulator-min-microvolt = <0x61a80>;
							regulator-max-microvolt = <0x13d620>;
							regulator-always-on;
							regulator-ramp-delay = <0x1770>;
							regulator-initial-mode = <0x01>;
							phandle = <0x2e>;
						};

						BUCK2 {
							regulator-name = "vdd_cpucl0";
							regulator-min-microvolt = <0x61a80>;
							regulator-max-microvolt = <0x13d620>;
							regulator-always-on;
							regulator-ramp-delay = <0x1770>;
							regulator-initial-mode = <0x01>;
							phandle = <0x2f>;
						};

						BUCK3 {
							regulator-name = "vdd_cpucl1";
							regulator-min-microvolt = <0x61a80>;
							regulator-max-microvolt = <0x13d620>;
							regulator-always-on;
							regulator-ramp-delay = <0x1770>;
							regulator-initial-mode = <0x01>;
							phandle = <0x30>;
						};

						BUCK5 {
							regulator-name = "vdd_mif";
							regulator-min-microvolt = <0x61a80>;
							regulator-max-microvolt = <0x13d620>;
							regulator-always-on;
							regulator-ramp-delay = <0x1770>;
							regulator-initial-mode = <0x01>;
							phandle = <0x31>;
						};

						BUCK6 {
							regulator-name = "vdd_cam";
							regulator-min-microvolt = <0x61a80>;
							regulator-max-microvolt = <0x13d620>;
							regulator-always-on;
							regulator-ramp-delay = <0x1770>;
							regulator-initial-mode = <0x01>;
							phandle = <0x32>;
						};

						BUCK7 {
							regulator-name = "vdd_lldo1s";
							regulator-min-microvolt = <0x61a80>;
							regulator-max-microvolt = <0x155cc0>;
							regulator-always-on;
							regulator-ramp-delay = <0x1770>;
							regulator-initial-mode = <0x03>;
							phandle = <0x33>;
						};

						BUCK8 {
							regulator-name = "vdd_lldo2s";
							regulator-min-microvolt = <0x61a80>;
							regulator-max-microvolt = <0x155cc0>;
							regulator-always-on;
							regulator-ramp-delay = <0x1770>;
							regulator-initial-mode = <0x03>;
							phandle = <0x34>;
						};

						BUCKB {
							regulator-name = "vdd_hldo";
							regulator-min-microvolt = <0x2dc6c0>;
							regulator-max-microvolt = <0x36ee80>;
							regulator-always-on;
							regulator-ramp-delay = <0x1770>;
							regulator-initial-mode = <0x03>;
							phandle = <0x35>;
						};

						LDO1 {
							regulator-name = "vdd_ldo1s";
							regulator-min-microvolt = <0x61a80>;
							regulator-max-microvolt = <0x13d620>;
							regulator-always-on;
							regulator-ramp-delay = <0x2ee0>;
							regulator-initial-mode = <0x01>;
							phandle = <0x36>;
						};

						LDO2 {
							regulator-name = "vdd_ldo2s";
							regulator-min-microvolt = <0x61a80>;
							regulator-max-microvolt = <0x13d620>;
							regulator-always-on;
							regulator-ramp-delay = <0x2ee0>;
							regulator-initial-mode = <0x01>;
							phandle = <0x37>;
						};

						LDO4 {
							regulator-name = "vdd_ldo4s";
							regulator-min-microvolt = <0x61a80>;
							regulator-max-microvolt = <0x13d620>;
							regulator-always-on;
							regulator-ramp-delay = <0x2ee0>;
							regulator-initial-mode = <0x01>;
							phandle = <0x38>;
						};

						LDO5 {
							regulator-name = "vdd_ldo5s";
							regulator-min-microvolt = <0x61a80>;
							regulator-max-microvolt = <0x13d620>;
							regulator-always-on;
							regulator-ramp-delay = <0x2ee0>;
							regulator-initial-mode = <0x01>;
							phandle = <0x39>;
						};

						LDO6 {
							regulator-name = "vdd_ldo6s";
							regulator-min-microvolt = <0xb1008>;
							regulator-max-microvolt = <0x13d620>;
							regulator-always-on;
							regulator-ramp-delay = <0x2ee0>;
							regulator-initial-mode = <0x01>;
							phandle = <0x3a>;
						};

						LDO8 {
							regulator-name = "vdd_ldo8s";
							regulator-min-microvolt = <0x1b7740>;
							regulator-max-microvolt = <0x337f98>;
							regulator-always-on;
							regulator-ramp-delay = <0x2ee0>;
							regulator-initial-mode = <0x03>;
							phandle = <0x12>;
						};

						LDO12 {
							regulator-name = "vqmmc";
							regulator-min-microvolt = <0x1b7740>;
							regulator-max-microvolt = <0x337f98>;
							regulator-ramp-delay = <0x2ee0>;
							regulator-initial-mode = <0x01>;
							phandle = <0x3b>;
						};

						LDO16 {
							regulator-name = "vdd_ldo16s";
							regulator-min-microvolt = <0x2dc6c0>;
							regulator-max-microvolt = <0x2dc6c0>;
							regulator-always-on;
							regulator-ramp-delay = <0x2ee0>;
							regulator-initial-mode = <0x03>;
							phandle = <0x0b>;
						};

						LDO22 {
							regulator-name = "vdd_ldo22s";
							regulator-min-microvolt = <0xb1008>;
							regulator-max-microvolt = <0x13d620>;
							regulator-ramp-delay = <0x2ee0>;
							regulator-initial-mode = <0x03>;
							phandle = <0x3c>;
						};

						LDO23 {
							regulator-name = "vdd_ldo23s";
							regulator-min-microvolt = <0xb1008>;
							regulator-max-microvolt = <0x13d620>;
							regulator-always-on;
							regulator-ramp-delay = <0x2ee0>;
							regulator-initial-mode = <0x03>;
							phandle = <0x3d>;
						};

						LDO24 {
							regulator-name = "vdd_ldo24s";
							regulator-min-microvolt = <0x1b7740>;
							regulator-max-microvolt = <0x337f98>;
							regulator-ramp-delay = <0x2ee0>;
							regulator-initial-mode = <0x03>;
							phandle = <0x0c>;
						};

						LDO25 {
							regulator-name = "vmmc";
							regulator-min-microvolt = <0x1b7740>;
							regulator-max-microvolt = <0x337f98>;
							regulator-ramp-delay = <0x2ee0>;
							regulator-initial-mode = <0x03>;
							phandle = <0x3e>;
						};

						LDO26 {
							regulator-name = "vdd_ldo26s";
							regulator-min-microvolt = <0x1b7740>;
							regulator-max-microvolt = <0x337f98>;
							regulator-always-on;
							regulator-ramp-delay = <0x2ee0>;
							regulator-initial-mode = <0x03>;
							phandle = <0x3f>;
						};

						LDO27 {
							regulator-name = "vdd_ldo27s";
							regulator-min-microvolt = <0x1b7740>;
							regulator-max-microvolt = <0x337f98>;
							regulator-ramp-delay = <0x2ee0>;
							phandle = <0x40>;
						};
					};
				};
			};

			gnss_mailbox {
				status = "okay";
				compatible = "samsung,exynos-gnss-mailbox";
				reg = <0x00 0x11980000 0x200>;
				interrupt-parent = <0xffffffff>;
				interrupts = <0x00 0x25 0x04>;
				mbox,name = "gnss_mailbox";
				mbox,id = <0x00>;
				num_shared_reg = <0x04>;
				shared_reg_offset = <0x100>;
				use_sw_reset_reg = <0x00>;
				phandle = <0x06>;
			};

			gnssif {
				status = "okay";
				compatible = "samsung,exynos-gnss";
				interrupt-parent = <0xffffffff>;
				interrupts = <0x00 0x16 0x04 0x00 0x10e 0x04 0x00 0x10d 0x04 0x00 0x10c 0x01>;
				interrupt-names = "ACTIVE\0WATCHDOG\0WAKEUP\0SW_INIT";
				shmem,name = "KEPLER";
				device_node_name = "gnss_ipc";
				mbox_info = <0x06>;
				mbx,int_bcmd = <0x00>;
				mbx,int_req_fault_info = <0x01>;
				mbx,int_ipc_msg = <0x02>;
				mbx,int_ack_wake_set = <0x03>;
				mbx,int_ack_wake_clr = <0x04>;
				mbx,irq_bcmd = <0x00>;
				mbx,irq_rsp_fault_info = <0x01>;
				mbx,irq_ipc_msg = <0x02>;
				mbx,irq_req_wake_clr = <0x04>;
				mbx,irq_simple_lock = <0x0f>;
				mbx,reg_bcmd_ctrl = <0x00 0x01 0x02 0x03>;
				memory-region = <0xffffffff>;
				reg_rx_ipc_msg = <0x01 0x05>;
				reg_tx_ipc_msg = <0x01 0x04>;
				reg_rx_head = <0x01 0x03>;
				reg_rx_tail = <0x01 0x02>;
				reg_tx_head = <0x01 0x01>;
				reg_tx_tail = <0x01 0x00>;
				fault_info = <0x01 0x200000 0x180000>;
				shmem,code_offset = <0x00>;
				shmem,code_allowed_size = <0x380000>;
				shmem,ipc_offset = <0x380000>;
				shmem,ipc_size = <0x80000>;
				shmem,ipc_rx_offset = <0x00>;
				shmem,ipc_rx_size = <0x40000>;
				shmem,ipc_tx_offset = <0x40000>;
				shmem,ipc_tx_size = <0x3ff80>;
				shmem,ipc_reg_offset = <0x7ff80>;
				shmem,ipc_reg_size = <0x80>;
			};

			audio-codec-dummy {
				compatible = "snd-soc-dummy";
				#sound-dai-cells = <0x00>;
				phandle = <0x41>;
			};

			audio-cpu-dummy {
				compatible = "samsung,dummy-cpu";
				#sound-dai-cells = <0x00>;
				phandle = <0x42>;
			};

			abox_synchronized_ipc {
				compatible = "samsung,abox-synchronized-ipc";
				#sound-dai-cells = <0x01>;
				abox = <0xffffffff>;
				phandle = <0x43>;
			};

			sound {
				compatible = "samsung,exynos-sound";
				samsung,routing = "PAD DPDM\0DMIC1\0PAD DPDM\0DMIC2\0RECEIVER\0Left OUTL\0SPEAKER\0Right OUTL\0BLUETOOTH SPK\0ABOX UAIF3 Playback\0ABOX UAIF3 Capture\0BLUETOOTH MIC\0USB SPK\0ABOX USB Playback\0ABOX USB Capture\0USB MIC\0FWD SPK\0ABOX FWD Playback\0ABOX FWD Capture\0FWD MIC\0VTS Virtual Output\0VTS Virtual Output Mux\0ABOX SPDY Capture\0VINPUT_FM";
				samsung,codec = <0x07 0x08>;
				samsung,prefix = "Left\0Right";
				samsung,aux = <0xffffffff 0xffffffff>;

				rdma0 {

					cpu {
						sound-dai = <0xffffffff 0x00>;
					};

					platform {
						sound-dai = <0xffffffff 0x00>;
					};
				};

				rdma1 {

					cpu {
						sound-dai = <0xffffffff 0x00>;
					};

					platform {
						sound-dai = <0xffffffff 0x00>;
					};
				};

				rdma2 {

					cpu {
						sound-dai = <0xffffffff 0x00>;
					};

					platform {
						sound-dai = <0xffffffff 0x00>;
					};
				};

				rdma3 {

					cpu {
						sound-dai = <0xffffffff 0x00>;
					};

					platform {
						sound-dai = <0xffffffff 0x00>;
					};
				};

				rdma4 {

					cpu {
						sound-dai = <0xffffffff 0x00>;
					};

					platform {
						sound-dai = <0xffffffff 0x00>;
					};
				};

				rdma5 {

					cpu {
						sound-dai = <0xffffffff 0x00>;
					};

					platform {
						sound-dai = <0xffffffff 0x00>;
					};
				};

				rdma6 {

					cpu {
						sound-dai = <0xffffffff 0x00>;
					};

					platform {
						sound-dai = <0xffffffff 0x00>;
					};
				};

				rdma7 {

					cpu {
						sound-dai = <0xffffffff 0x00>;
					};

					platform {
						sound-dai = <0xffffffff 0x00>;
					};
				};

				rdma8 {

					cpu {
						sound-dai = <0xffffffff 0x00>;
					};

					platform {
						sound-dai = <0xffffffff 0x00>;
					};
				};

				rdma9 {

					cpu {
						sound-dai = <0xffffffff 0x00>;
					};

					platform {
						sound-dai = <0xffffffff 0x00>;
					};
				};

				rdma10 {

					cpu {
						sound-dai = <0xffffffff 0x00>;
					};

					platform {
						sound-dai = <0xffffffff 0x00>;
					};
				};

				rdma11 {

					cpu {
						sound-dai = <0xffffffff 0x00>;
					};

					platform {
						sound-dai = <0xffffffff 0x00>;
					};
				};

				wdma0 {

					cpu {
						sound-dai = <0xffffffff 0x00>;
					};

					platform {
						sound-dai = <0xffffffff 0x00>;
					};
				};

				wdma1 {

					cpu {
						sound-dai = <0xffffffff 0x00>;
					};

					platform {
						sound-dai = <0xffffffff 0x00>;
					};
				};

				wdma2 {

					cpu {
						sound-dai = <0xffffffff 0x00>;
					};

					platform {
						sound-dai = <0xffffffff 0x00>;
					};
				};

				wdma3 {

					cpu {
						sound-dai = <0xffffffff 0x00>;
					};

					platform {
						sound-dai = <0xffffffff 0x00>;
					};
				};

				wdma4 {

					cpu {
						sound-dai = <0xffffffff 0x00>;
					};

					platform {
						sound-dai = <0xffffffff 0x00>;
					};
				};

				wdma5 {

					cpu {
						sound-dai = <0xffffffff 0x00>;
					};

					platform {
						sound-dai = <0xffffffff 0x00>;
					};
				};

				wdma6 {

					cpu {
						sound-dai = <0xffffffff 0x00>;
					};

					platform {
						sound-dai = <0xffffffff 0x00>;
					};
				};

				wdma7 {

					cpu {
						sound-dai = <0xffffffff 0x00>;
					};

					platform {
						sound-dai = <0xffffffff 0x00>;
					};
				};

				wdma8 {

					cpu {
						sound-dai = <0xffffffff 0x00>;
					};

					platform {
						sound-dai = <0xffffffff 0x00>;
					};
				};

				wdma9 {

					cpu {
						sound-dai = <0xffffffff 0x00>;
					};

					platform {
						sound-dai = <0xffffffff 0x00>;
					};
				};

				wdma10 {

					cpu {
						sound-dai = <0xffffffff 0x00>;
					};

					platform {
						sound-dai = <0xffffffff 0x00>;
					};
				};

				wdma11 {

					cpu {
						sound-dai = <0xffffffff 0x00>;
					};

					platform {
						sound-dai = <0xffffffff 0x00>;
					};
				};

				vts0 {

					cpu {
						sound-dai = <0xffffffff 0x00>;
					};

					platform {
						sound-dai = <0xffffffff>;
					};
				};

				vts1 {

					cpu {
						sound-dai = <0xffffffff 0x01>;
					};

					platform {
						sound-dai = <0xffffffff>;
					};
				};

				dual0 {

					cpu {
						sound-dai = <0xffffffff>;
					};

					platform {
						sound-dai = <0xffffffff>;
					};
				};

				dual1 {

					cpu {
						sound-dai = <0xffffffff>;
					};

					platform {
						sound-dai = <0xffffffff>;
					};
				};

				dual2 {

					cpu {
						sound-dai = <0xffffffff>;
					};

					platform {
						sound-dai = <0xffffffff>;
					};
				};

				dual3 {

					cpu {
						sound-dai = <0xffffffff>;
					};

					platform {
						sound-dai = <0xffffffff>;
					};
				};

				dual4 {

					cpu {
						sound-dai = <0xffffffff>;
					};

					platform {
						sound-dai = <0xffffffff>;
					};
				};

				dual5 {

					cpu {
						sound-dai = <0xffffffff>;
					};

					platform {
						sound-dai = <0xffffffff>;
					};
				};

				dual6 {

					cpu {
						sound-dai = <0xffffffff>;
					};

					platform {
						sound-dai = <0xffffffff>;
					};
				};

				dual7 {

					cpu {
						sound-dai = <0xffffffff>;
					};

					platform {
						sound-dai = <0xffffffff>;
					};
				};

				dual8 {

					cpu {
						sound-dai = <0xffffffff>;
					};

					platform {
						sound-dai = <0xffffffff>;
					};
				};

				dual9 {

					cpu {
						sound-dai = <0xffffffff>;
					};

					platform {
						sound-dai = <0xffffffff>;
					};
				};

				dual10 {

					cpu {
						sound-dai = <0xffffffff>;
					};

					platform {
						sound-dai = <0xffffffff>;
					};
				};

				dual11 {

					cpu {
						sound-dai = <0xffffffff>;
					};

					platform {
						sound-dai = <0xffffffff>;
					};
				};

				ddma0 {

					cpu {
						sound-dai = <0xffffffff>;
					};

					platform {
						sound-dai = <0xffffffff>;
					};
				};

				ddma1 {

					cpu {
						sound-dai = <0xffffffff>;
					};

					platform {
						sound-dai = <0xffffffff>;
					};
				};

				ddma2 {

					cpu {
						sound-dai = <0xffffffff>;
					};

					platform {
						sound-dai = <0xffffffff>;
					};
				};

				ddma3 {

					cpu {
						sound-dai = <0xffffffff>;
					};

					platform {
						sound-dai = <0xffffffff>;
					};
				};

				ddma4 {

					cpu {
						sound-dai = <0xffffffff>;
					};

					platform {
						sound-dai = <0xffffffff>;
					};
				};

				ddma5 {

					cpu {
						sound-dai = <0xffffffff>;
					};

					platform {
						sound-dai = <0xffffffff>;
					};
				};

				uaif0 {
					format = "i2s";

					cpu {
						sound-dai = <0xffffffff>;
					};
				};

				uaif1 {
					format = "i2s";

					cpu {
						sound-dai = <0xffffffff>;
					};

					codec {
						sound-dai = <0x07 0x00 0x08 0x00>;
					};
				};

				uaif2 {
					format = "dsp_a";

					cpu {
						sound-dai = <0xffffffff>;
					};
				};

				uaif3 {
					format = "i2s";
					bitclock-master;
					frame-master;

					cpu {
						sound-dai = <0xffffffff>;
					};
				};

				uaif4 {
					format = "dsp_a";

					cpu {
						sound-dai = <0xffffffff>;
					};
				};

				uaif5 {
					format = "dsp_a";

					cpu {
						sound-dai = <0xffffffff>;
					};
				};

				uaif6 {
					format = "dsp_a";
					bitclock-master;
					bitclock-inversion;
					frame-master;

					cpu {
						sound-dai = <0xffffffff>;
					};

					codec {
						sound-dai = <0xffffffff 0x00>;
					};
				};

				dsif0 {
					format = "pdm";

					cpu {
						sound-dai = <0xffffffff>;
					};
				};

				spdy {

					cpu {
						sound-dai = <0xffffffff>;
					};
				};

				udma_rd0 {

					cpu {
						sound-dai = <0xffffffff>;
					};
				};

				udma_rd1 {

					cpu {
						sound-dai = <0xffffffff>;
					};
				};

				udma_wr0 {

					cpu {
						sound-dai = <0xffffffff>;
					};
				};

				udma_wr1 {

					cpu {
						sound-dai = <0xffffffff>;
					};
				};

				udma_wr_dual0 {

					cpu {
						sound-dai = <0xffffffff>;
					};
				};

				udma_wr_dual1 {

					cpu {
						sound-dai = <0xffffffff>;
					};
				};

				udma_wr_dbg0 {

					cpu {
						sound-dai = <0xffffffff>;
					};
				};

				rdma0_be {

					cpu {
						sound-dai = <0xffffffff 0x01>;
					};

					platform {
						sound-dai = <0xffffffff 0x01>;
					};
				};

				rdma1_be {

					cpu {
						sound-dai = <0xffffffff 0x01>;
					};

					platform {
						sound-dai = <0xffffffff 0x01>;
					};
				};

				rdma2_be {

					cpu {
						sound-dai = <0xffffffff 0x01>;
					};

					platform {
						sound-dai = <0xffffffff 0x01>;
					};
				};

				rdma3_be {

					cpu {
						sound-dai = <0xffffffff 0x01>;
					};

					platform {
						sound-dai = <0xffffffff 0x01>;
					};
				};

				rdma4_be {

					cpu {
						sound-dai = <0xffffffff 0x01>;
					};

					platform {
						sound-dai = <0xffffffff 0x01>;
					};
				};

				rdma5_be {

					cpu {
						sound-dai = <0xffffffff 0x01>;
					};

					platform {
						sound-dai = <0xffffffff 0x01>;
					};
				};

				rdma6_be {

					cpu {
						sound-dai = <0xffffffff 0x01>;
					};

					platform {
						sound-dai = <0xffffffff 0x01>;
					};
				};

				rdma7_be {

					cpu {
						sound-dai = <0xffffffff 0x01>;
					};

					platform {
						sound-dai = <0xffffffff 0x01>;
					};
				};

				rdma8_be {

					cpu {
						sound-dai = <0xffffffff 0x01>;
					};

					platform {
						sound-dai = <0xffffffff 0x01>;
					};
				};

				rdma9_be {

					cpu {
						sound-dai = <0xffffffff 0x01>;
					};

					platform {
						sound-dai = <0xffffffff 0x01>;
					};
				};

				rdma10_be {

					cpu {
						sound-dai = <0xffffffff 0x01>;
					};

					platform {
						sound-dai = <0xffffffff 0x01>;
					};
				};

				rdma11_be {

					cpu {
						sound-dai = <0xffffffff 0x01>;
					};

					platform {
						sound-dai = <0xffffffff 0x01>;
					};
				};

				wdma0_be {

					cpu {
						sound-dai = <0xffffffff 0x01>;
					};

					platform {
						sound-dai = <0xffffffff 0x01>;
					};
				};

				wdma1_be {

					cpu {
						sound-dai = <0xffffffff 0x01>;
					};

					platform {
						sound-dai = <0xffffffff 0x01>;
					};
				};

				wdma2_be {

					cpu {
						sound-dai = <0xffffffff 0x01>;
					};

					platform {
						sound-dai = <0xffffffff 0x01>;
					};
				};

				wdma3_be {

					cpu {
						sound-dai = <0xffffffff 0x01>;
					};

					platform {
						sound-dai = <0xffffffff 0x01>;
					};
				};

				wdma4_be {

					cpu {
						sound-dai = <0xffffffff 0x01>;
					};

					platform {
						sound-dai = <0xffffffff 0x01>;
					};
				};

				wdma5_be {

					cpu {
						sound-dai = <0xffffffff 0x01>;
					};

					platform {
						sound-dai = <0xffffffff 0x01>;
					};
				};

				wdma6_be {

					cpu {
						sound-dai = <0xffffffff 0x01>;
					};

					platform {
						sound-dai = <0xffffffff 0x01>;
					};
				};

				wdma7_be {

					cpu {
						sound-dai = <0xffffffff 0x01>;
					};

					platform {
						sound-dai = <0xffffffff 0x01>;
					};
				};

				wdma8_be {

					cpu {
						sound-dai = <0xffffffff 0x01>;
					};

					platform {
						sound-dai = <0xffffffff 0x01>;
					};
				};

				wdma9_be {

					cpu {
						sound-dai = <0xffffffff 0x01>;
					};

					platform {
						sound-dai = <0xffffffff 0x01>;
					};
				};

				wdma10_be {

					cpu {
						sound-dai = <0xffffffff 0x01>;
					};

					platform {
						sound-dai = <0xffffffff 0x01>;
					};
				};

				wdma11_be {

					cpu {
						sound-dai = <0xffffffff 0x01>;
					};

					platform {
						sound-dai = <0xffffffff 0x01>;
					};
				};

				usb {

					cpu {
						sound-dai = <0xffffffff 0x00>;
					};
				};

				fwd {

					cpu {
						sound-dai = <0xffffffff 0x01>;
					};
				};
			};
		};
	};

	fragment@1 {
		target = <0xffffffff>;

		__overlay__ {
			#address-cells = <0x01>;
			#size-cells = <0x00>;
			status = "okay";
			samsung,reset-before-trans;

			touchscreen@49 {
				status = "ok";
				compatible = "stm,fts_touch";
				reg = <0x49>;
				pinctrl-names = "default";
				pinctrl-0 = <0x09>;
				dvdd-supply = <0x0a>;
				avdd-supply = <0x0b>;
				stm,irq_gpio = <0xffffffff 0x03 0x00>;
				stm,max_coords = <0xfff 0xfff>;
				stm,tclm_level = <0x02>;
				stm,afe_base = <0x14>;
				stm,bringup = <0x01>;
				stm,support_fod;
				stm,enable_settings_aot;
				stm,ss_touch_num = <0x01>;
			};
		};
	};

	fragment@2 {
		target = <0xffffffff>;

		__overlay__ {
			vcc-supply = <0x0c>;
			vccq2-supply = <0x0d>;
		};
	};

	fragment@3 {
		target = <0xffffffff>;

		__overlay__ {

			ext-bin@0 {
				compatible = "samsung,abox-ext-bin";
				samsung,name = "dax_param.bin";
				samsung,area = <0x01>;
				samsung,offset = <0x510000>;
				samsung,changable;
				phandle = <0x44>;
			};

			ext-bin@1 {
				compatible = "samsung,abox-ext-bin";
				samsung,name = "AP_AUDIO_SLSI.bin";
				samsung,area = <0x01>;
				samsung,offset = <0x52e000>;
				samsung,changable;
				phandle = <0x45>;
			};

			ext-bin@2 {
				compatible = "samsung,abox-ext-bin";
				samsung,name = "APBargeIn_AUDIO_SLSI.bin";
				samsung,area = <0x01>;
				samsung,offset = <0x5da800>;
				samsung,changable;
				phandle = <0x46>;
			};

			ext-bin@3 {
				compatible = "samsung,abox-ext-bin";
				samsung,name = "APBiBF_AUDIO_SLSI.bin";
				samsung,area = <0x01>;
				samsung,offset = <0x5dd800>;
				samsung,changable;
				phandle = <0x47>;
			};

			ext-bin@4 {
				compatible = "samsung,abox-ext-bin";
				samsung,name = "APDV_AUDIO_SLSI.bin";
				samsung,area = <0x01>;
				samsung,offset = <0x5de800>;
				samsung,changable;
				phandle = <0x48>;
			};

			ext-bin@5 {
				compatible = "samsung,abox-ext-bin";
				samsung,name = "SoundBoosterParam.bin";
				samsung,area = <0x01>;
				samsung,offset = <0x65e800>;
				samsung,changable;
				phandle = <0x49>;
			};

			ext-bin@6 {
				compatible = "samsung,abox-ext-bin";
				samsung,name = "atune.bin";
				samsung,area = <0x01>;
				samsung,offset = "\0f(";
				samsung,changable;
				phandle = <0x4a>;
			};

			ext-bin@7 {
				compatible = "samsung,abox-ext-bin";
				samsung,name = "rxse.bin";
				samsung,area = <0x01>;
				samsung,offset = "\0lP";
				phandle = <0x4b>;
			};

			ext-bin@8 {
				compatible = "samsung,abox-ext-bin";
				samsung,name = "avsyncmix.bin";
				samsung,area = <0x01>;
				samsung,offset = "\0{x";
				phandle = <0x4c>;
			};

			ext-bin@9 {
				compatible = "samsung,abox-ext-bin";
				samsung,name = "txse1.bin";
				samsung,area = <0x01>;
				samsung,offset = <0x1800000>;
				phandle = <0x4d>;
			};

			ext-bin@10 {
				compatible = "samsung,abox-ext-bin";
				samsung,name = "txse2.bin";
				samsung,area = <0x01>;
				samsung,offset = <0x1e00000>;
				phandle = <0x4e>;
			};

			ext-bin@11 {
				compatible = "samsung,abox-ext-bin";
				samsung,name = "bidirmic.bin";
				samsung,area = <0x01>;
				samsung,offset = <0x1e72800>;
				phandle = <0x4f>;
			};

			ext-bin@12 {
				compatible = "samsung,abox-ext-bin";
				samsung,name = "volumemonitor.bin";
				samsung,area = <0x01>;
				samsung,offset = <0x1f27800>;
				phandle = <0x50>;
			};

			ext-bin@13 {
				compatible = "samsung,abox-ext-bin";
				samsung,name = "sb_others.bin";
				samsung,area = <0x01>;
				samsung,offset = <0x1f40800>;
				phandle = <0x51>;
			};

			ext-bin@14 {
				compatible = "samsung,abox-ext-bin";
				samsung,name = "listenbackeffect.bin";
				samsung,area = <0x01>;
				samsung,offset = <0x206c800>;
				phandle = <0x52>;
			};

			ext-bin@15 {
				compatible = "samsung,abox-ext-bin";
				samsung,name = "a2dpcom.bin";
				samsung,area = <0x01>;
				samsung,offset = <0x20d0800>;
				phandle = <0x53>;
			};

			ext-bin@16 {
				compatible = "samsung,abox-ext-bin";
				samsung,name = "dolby.bin";
				samsung,area = <0x01>;
				samsung,offset = <0x2c0000>;
				phandle = <0x54>;
			};

			ext-bin@17 {
				compatible = "samsung,abox-ext-bin";
				samsung,name = "tfa9878.bin";
				samsung,area = <0x01>;
				samsung,offset = <0x1480000>;
				phandle = <0x55>;
			};

			ext-bin@18 {
				compatible = "samsung,abox-ext-bin";
				samsung,name = "sb_music.bin";
				samsung,area = <0x01>;
				samsung,offset = <0x2250800>;
				phandle = <0x56>;
			};
		};
	};

	fragment@4 {
		target = <0xffffffff>;

		__overlay__ {
			pinctrl-names;
		};
	};

	fragment@5 {
		target = <0xffffffff>;

		__overlay__ {
			pinctrl-names;
		};
	};

	fragment@6 {
		target = <0xffffffff>;

		__overlay__ {
			pinctrl-names = "dmic0_default\0dmic1_default\0dmic2_default\0amic0_default\0amic1_default\0amic2_default\0dmic0_idle\0dmic1_idle\0dmic2_idle\0default";
			pinctrl-0 = <0xffffffff 0xffffffff 0x0e>;
			pinctrl-1 = <0xffffffff 0xffffffff 0x0f>;
			pinctrl-2 = <0xffffffff 0xffffffff>;
			pinctrl-3 = <0xffffffff 0xffffffff>;
			pinctrl-4 = <0xffffffff 0xffffffff>;
			pinctrl-5 = <0xffffffff 0xffffffff>;
			pinctrl-6 = <0xffffffff 0xffffffff 0x10>;
			pinctrl-7 = <0xffffffff 0xffffffff 0x11>;
			pinctrl-8 = <0xffffffff 0xffffffff>;
			pinctrl-9;
		};
	};

	fragment@7 {
		target = <0xffffffff>;

		__overlay__ {
			#address-cells = <0x01>;
			#size-cells = <0x00>;
			status = "okay";
			clock-frequency = <0x61a80>;

			tfa98xx@34 {
				#sound-dai-cells = <0x01>;
				compatible = "tfa,tfa98xx";
				reg = <0x34>;
				phandle = <0x07>;
			};

			tfa98xx@35 {
				#sound-dai-cells = <0x01>;
				compatible = "tfa,tfa98xx";
				reg = <0x35>;
				phandle = <0x08>;
			};
		};
	};

	fragment@8 {
		target = <0xffffffff>;

		__overlay__ {
			bootargs_ext = [00];
		};
	};

	fragment@9 {
		target = <0xffffffff>;

		__overlay__ {
			status = "okay";
		};
	};

	fragment@10 {
		target = <0xffffffff>;

		__overlay__ {
			status = "okay";

			dwc3 {
				dr_mode = "peripheral";
				maximum-speed = "high-speed";
			};
		};
	};

	fragment@11 {
		target = <0xffffffff>;

		__overlay__ {
			status = "okay";
			maximum-speed = "high-speed";
			usb_audio_offloading = <0x01>;
			abox = <0xffffffff>;
			xhci_l2_support = <0x01>;
			xhci_use_uram_for_audio = <0x01>;
			vdd33_usb-supply = <0x12>;
		};
	};

	fragment@12 {
		target = <0xffffffff>;

		__overlay__ {
			status = "okay";
			use_default_tune_val = <0x01>;
			hs_tune_param = <0x13>;
			vdd33_usb-supply = <0x12>;
		};
	};

	fragment@13 {
		target = <0xffffffff>;

		__overlay__ {

			attn-irq {
				samsung,pins = "gpa0-3";
				samsung,pin-function = <0x0f>;
				samsung,pin-pud = <0x03>;
				samsung,pin-drv = <0x03>;
				phandle = <0x09>;
			};

			attn-input {
				samsung,pins = "gpa0-3";
				samsung,pin-function = <0x00>;
				samsung,pin-pud = <0x01>;
				phandle = <0x57>;
			};

			pm-wrstbi {
				samsung,pins = "gpc1-0";
				samsung,pin-con-pdn = <0x03>;
				samsung,pin-pud-pdn = <0x00>;
				phandle = <0x04>;
			};

			key-voldown {
				samsung,pins = "gpa0-7";
				samsung,pin-function = <0x0f>;
				samsung,pin-pud = <0x03>;
				samsung,pin-drv = <0x03>;
				phandle = <0x02>;
			};

			key-volup {
				samsung,pins = "gpa1-0";
				samsung,pin-function = <0x0f>;
				samsung,pin-pud = <0x03>;
				samsung,pin-drv = <0x03>;
				phandle = <0x03>;
			};

			dwmmc2_cd_ext_irq {
				samsung,pins = "gpc0-0";
				samsung,pin-function = <0x0f>;
				samsung,pin-pud = <0x00>;
				samsung,pin-drv = <0x03>;
				phandle = <0x14>;
			};

			dmic1-en {
				samsung,pins = "gpc2-0";
				samsung,pin-function = <0x01>;
				samsung,pin-pud = <0x00>;
				samsung,pin-val = <0x01>;
				phandle = <0x0e>;
			};

			dmic1-en-idle {
				samsung,pins = "gpc2-0";
				samsung,pin-function = <0x00>;
				samsung,pin-pud = <0x00>;
				samsung,pin-val = <0x00>;
				phandle = <0x10>;
			};

			dmic2-en {
				samsung,pins = "gpc3-0";
				samsung,pin-function = <0x01>;
				samsung,pin-pud = <0x00>;
				samsung,pin-val = <0x01>;
				phandle = <0x0f>;
			};

			dmic2-en-idle {
				samsung,pins = "gpc3-0";
				samsung,pin-function = <0x00>;
				samsung,pin-pud = <0x00>;
				samsung,pin-val = <0x00>;
				phandle = <0x11>;
			};
		};
	};

	fragment@14 {
		target = <0xffffffff>;

		__overlay__ {

			smpl-warn {
				samsung,pins = "gpg0-0";
				samsung,pin-function = <0x0f>;
				samsung,pin-pud = <0x00>;
				samsung,pin-drv = <0x00>;
				phandle = <0x05>;
			};
		};
	};

	fragment@15 {
		target = <0xffffffff>;

		__overlay__ {
			#address-cells = <0x01>;
			#size-cells = <0x00>;
			status = "okay";

			s2mpb03_pmic@56 {
				compatible = "samsung,s2mpb03pmic";
				reg = <0x56>;
				s2mpb03,wakeup;

				regulators {

					s2mpb03-ldo1 {
						regulator-name = "VDDD_1.05V_SUB";
						regulator-min-microvolt = <0x100590>;
						regulator-max-microvolt = <0x100590>;
						phandle = <0x58>;
					};

					s2mpb03-ldo2 {
						regulator-name = "VDDD_1.05V_CAM";
						regulator-min-microvolt = <0x100590>;
						regulator-max-microvolt = <0x100590>;
						phandle = <0x59>;
					};

					s2mpb03-ldo3 {
						regulator-name = "VDDIO_1.8V_CAM";
						regulator-min-microvolt = <0x1b7740>;
						regulator-max-microvolt = <0x1b7740>;
						phandle = <0x5a>;
					};

					s2mpb03-ldo4 {
						regulator-name = "S2MPB03_LD04";
						regulator-min-microvolt = <0xaae60>;
						regulator-max-microvolt = <0xfa3e8>;
						phandle = <0x5b>;
					};

					s2mpb03-ldo5 {
						regulator-name = "VDDA_2.8V_CAM";
						regulator-min-microvolt = <0x20ce70>;
						regulator-max-microvolt = <0x20ce70>;
						phandle = <0x5c>;
					};

					s2mpb03-ldo6 {
						regulator-name = "VDDA_2.8V_SUB";
						regulator-min-microvolt = <0x2ab980>;
						regulator-max-microvolt = <0x2ab980>;
						phandle = <0x5d>;
					};

					s2mpb03-ldo7 {
						regulator-name = "VDD_VM_2.8V_OIS";
						regulator-min-microvolt = <0x2ab980>;
						regulator-max-microvolt = <0x2ab980>;
						phandle = <0x5e>;
					};
				};
			};
		};
	};

	fragment@16 {
		target = <0xffffffff>;

		__overlay__ {
			#address-cells = <0x01>;
			#size-cells = <0x00>;

			drmpanel {
				compatible = "samsung,s6e3fc3";
				reset-gpios = <0xffffffff 0x00 0x00>;
				reg = <0x00>;
				phandle = <0x5f>;
			};
		};
	};

	fragment@17 {
		target = <0xffffffff>;

		__overlay__ {
			#address-cells = <0x01>;
			#size-cells = <0x00>;
			status = "okay";
			num-slots = <0x01>;
			supports-4bit;
			supports-cmd23;
			supports-erase;
			supports-highspeed;
			sd-uhs-sdr50;
			sd-uhs-sdr104;
			card-detect-gpio;
			bypass-for-allpass;
			use-fine-tuning;
			card-init-hwacg-ctrl;
			skip-init-mmc-scan;
			ssc-rate-mfr = <0x04>;
			ssc-rate-mrr = <0x1b>;
			qos-dvfs-level = <0x61a80>;
			fifo-depth = <0x40>;
			desc-size = <0x04>;
			card-detect-delay = <0xc8>;
			data-timeout = <0xc8>;
			hto-timeout = <0x50>;
			samsung,dw-mshc-ciu-div = <0x03>;
			clock-frequency = <0x2faf0800>;
			samsung,dw-mshc-sdr-timing = <0x03 0x00 0x02 0x01>;
			samsung,dw-mshc-ddr-timing = <0x03 0x00 0x02 0x01>;
			samsung,dw-mshc-sdr50-timing = <0x03 0x00 0x04 0x02>;
			samsung,dw-mshc-sdr104-timing = <0x03 0x00 0x03 0x00>;
			num-ref-clks = <0x09>;
			ciu_clkin = <0x19 0x32 0x32 0x19 0x32 0x64 0xc8 0x32 0x32>;
			clk-drive-number = <0x06>;
			pinctrl-names = "default\0fast-slew-rate-1x\0fast-slew-rate-2x\0fast-slew-rate-3x\0fast-slew-rate-4x\0fast-slew-rate-5x\0fast-slew-rate-6x";
			pinctrl-0 = <0xffffffff 0xffffffff 0xffffffff 0xffffffff 0x14>;
			pinctrl-1 = <0xffffffff>;
			pinctrl-2 = <0xffffffff>;
			pinctrl-3 = <0xffffffff>;
			pinctrl-4 = <0xffffffff>;
			pinctrl-5 = <0xffffffff>;
			pinctrl-6 = <0xffffffff>;
			card-detect = <0xffffffff 0x00 0x0f>;

			slot@0 {
				reg = <0x00>;
				bus-width = <0x04>;
				disable-wp;
			};
		};
	};

	fragment@18 {
		target = <0xffffffff>;

		__overlay__ {
			status = "okay";
		};
	};

	__symbols__ {
		cp_rmem1 = "/fragment@0/__overlay__/cp_rmem1";
		sec_battery = "/fragment@battery/__overlay__/battery";
		sm5714_fuelgauge = "/fragment@battery/__overlay__/sm5714-fuelgauge";
		sec_battery_cable = "/fragment@battery/__overlay__/cable-info";
		sec_battery_wireless_power_info = "/fragment@battery/__overlay__/wireless-power-info";
		usb_hs_tune = "/fragment@model/__overlay__/hs_tune";
		s2mpu13_gpadc = "/fragment@model/__overlay__/acpm_mfd_bus@11a00000/s2mpu13mfd@1f/s2mpu13-gpadc";
		s2mpu13_gpio = "/fragment@model/__overlay__/acpm_mfd_bus@11a00000/s2mpu13mfd@1f/s2mpu13-gpio";
		b1_reg = "/fragment@model/__overlay__/acpm_mfd_bus@11a00000/s2mpu13mfd@1f/regulators/BUCK1";
		b4_reg = "/fragment@model/__overlay__/acpm_mfd_bus@11a00000/s2mpu13mfd@1f/regulators/BUCK4";
		b5_reg = "/fragment@model/__overlay__/acpm_mfd_bus@11a00000/s2mpu13mfd@1f/regulators/BUCK5";
		b6_reg = "/fragment@model/__overlay__/acpm_mfd_bus@11a00000/s2mpu13mfd@1f/regulators/BUCK6";
		b8_reg = "/fragment@model/__overlay__/acpm_mfd_bus@11a00000/s2mpu13mfd@1f/regulators/BUCK8";
		b9_reg = "/fragment@model/__overlay__/acpm_mfd_bus@11a00000/s2mpu13mfd@1f/regulators/BUCK9";
		b10_reg = "/fragment@model/__overlay__/acpm_mfd_bus@11a00000/s2mpu13mfd@1f/regulators/BUCK10";
		l1_reg = "/fragment@model/__overlay__/acpm_mfd_bus@11a00000/s2mpu13mfd@1f/regulators/LDO1";
		l2_reg = "/fragment@model/__overlay__/acpm_mfd_bus@11a00000/s2mpu13mfd@1f/regulators/LDO2";
		l7_reg = "/fragment@model/__overlay__/acpm_mfd_bus@11a00000/s2mpu13mfd@1f/regulators/LDO7";
		l9_reg = "/fragment@model/__overlay__/acpm_mfd_bus@11a00000/s2mpu13mfd@1f/regulators/LDO9";
		l10_reg = "/fragment@model/__overlay__/acpm_mfd_bus@11a00000/s2mpu13mfd@1f/regulators/LDO10";
		l11_reg = "/fragment@model/__overlay__/acpm_mfd_bus@11a00000/s2mpu13mfd@1f/regulators/LDO11";
		l13_reg = "/fragment@model/__overlay__/acpm_mfd_bus@11a00000/s2mpu13mfd@1f/regulators/LDO13";
		l14_reg = "/fragment@model/__overlay__/acpm_mfd_bus@11a00000/s2mpu13mfd@1f/regulators/LDO14";
		l17_reg = "/fragment@model/__overlay__/acpm_mfd_bus@11a00000/s2mpu13mfd@1f/regulators/LDO17";
		l23_reg = "/fragment@model/__overlay__/acpm_mfd_bus@11a00000/s2mpu13mfd@1f/regulators/LDO23";
		l25_reg = "/fragment@model/__overlay__/acpm_mfd_bus@11a00000/s2mpu13mfd@1f/regulators/LDO25";
		l26_reg = "/fragment@model/__overlay__/acpm_mfd_bus@11a00000/s2mpu13mfd@1f/regulators/LDO26";
		l27_reg = "/fragment@model/__overlay__/acpm_mfd_bus@11a00000/s2mpu13mfd@1f/regulators/LDO27";
		s2mpu14_gpio = "/fragment@model/__overlay__/acpm_mfd_bus@11a01000/s2mpu14mfd@2f/s2mpu14-gpio";
		s_b1_reg = "/fragment@model/__overlay__/acpm_mfd_bus@11a01000/s2mpu14mfd@2f/regulators/BUCK1";
		s_b2_reg = "/fragment@model/__overlay__/acpm_mfd_bus@11a01000/s2mpu14mfd@2f/regulators/BUCK2";
		s_b3_reg = "/fragment@model/__overlay__/acpm_mfd_bus@11a01000/s2mpu14mfd@2f/regulators/BUCK3";
		s_b5_reg = "/fragment@model/__overlay__/acpm_mfd_bus@11a01000/s2mpu14mfd@2f/regulators/BUCK5";
		s_b6_reg = "/fragment@model/__overlay__/acpm_mfd_bus@11a01000/s2mpu14mfd@2f/regulators/BUCK6";
		s_b7_reg = "/fragment@model/__overlay__/acpm_mfd_bus@11a01000/s2mpu14mfd@2f/regulators/BUCK7";
		s_b8_reg = "/fragment@model/__overlay__/acpm_mfd_bus@11a01000/s2mpu14mfd@2f/regulators/BUCK8";
		s_bb_reg = "/fragment@model/__overlay__/acpm_mfd_bus@11a01000/s2mpu14mfd@2f/regulators/BUCKB";
		s_l1_reg = "/fragment@model/__overlay__/acpm_mfd_bus@11a01000/s2mpu14mfd@2f/regulators/LDO1";
		s_l2_reg = "/fragment@model/__overlay__/acpm_mfd_bus@11a01000/s2mpu14mfd@2f/regulators/LDO2";
		s_l4_reg = "/fragment@model/__overlay__/acpm_mfd_bus@11a01000/s2mpu14mfd@2f/regulators/LDO4";
		s_l5_reg = "/fragment@model/__overlay__/acpm_mfd_bus@11a01000/s2mpu14mfd@2f/regulators/LDO5";
		s_l6_reg = "/fragment@model/__overlay__/acpm_mfd_bus@11a01000/s2mpu14mfd@2f/regulators/LDO6";
		s_l8_reg = "/fragment@model/__overlay__/acpm_mfd_bus@11a01000/s2mpu14mfd@2f/regulators/LDO8";
		s_l12_reg = "/fragment@model/__overlay__/acpm_mfd_bus@11a01000/s2mpu14mfd@2f/regulators/LDO12";
		s_l16_reg = "/fragment@model/__overlay__/acpm_mfd_bus@11a01000/s2mpu14mfd@2f/regulators/LDO16";
		s_l22_reg = "/fragment@model/__overlay__/acpm_mfd_bus@11a01000/s2mpu14mfd@2f/regulators/LDO22";
		s_l23_reg = "/fragment@model/__overlay__/acpm_mfd_bus@11a01000/s2mpu14mfd@2f/regulators/LDO23";
		s_l24_reg = "/fragment@model/__overlay__/acpm_mfd_bus@11a01000/s2mpu14mfd@2f/regulators/LDO24";
		s_l25_reg = "/fragment@model/__overlay__/acpm_mfd_bus@11a01000/s2mpu14mfd@2f/regulators/LDO25";
		s_l26_reg = "/fragment@model/__overlay__/acpm_mfd_bus@11a01000/s2mpu14mfd@2f/regulators/LDO26";
		s_l27_reg = "/fragment@model/__overlay__/acpm_mfd_bus@11a01000/s2mpu14mfd@2f/regulators/LDO27";
		gnss_mailbox = "/fragment@model/__overlay__/gnss_mailbox";
		dummy_audio_codec = "/fragment@model/__overlay__/audio-codec-dummy";
		dummy_audio_cpu = "/fragment@model/__overlay__/audio-cpu-dummy";
		abox_synchronized_ipc = "/fragment@model/__overlay__/abox_synchronized_ipc";
		ext_bin_0 = "/fragment@3/__overlay__/ext-bin@0";
		ext_bin_1 = "/fragment@3/__overlay__/ext-bin@1";
		ext_bin_2 = "/fragment@3/__overlay__/ext-bin@2";
		ext_bin_3 = "/fragment@3/__overlay__/ext-bin@3";
		ext_bin_4 = "/fragment@3/__overlay__/ext-bin@4";
		ext_bin_5 = "/fragment@3/__overlay__/ext-bin@5";
		ext_bin_6 = "/fragment@3/__overlay__/ext-bin@6";
		ext_bin_7 = "/fragment@3/__overlay__/ext-bin@7";
		ext_bin_8 = "/fragment@3/__overlay__/ext-bin@8";
		ext_bin_9 = "/fragment@3/__overlay__/ext-bin@9";
		ext_bin_10 = "/fragment@3/__overlay__/ext-bin@10";
		ext_bin_11 = "/fragment@3/__overlay__/ext-bin@11";
		ext_bin_12 = "/fragment@3/__overlay__/ext-bin@12";
		ext_bin_13 = "/fragment@3/__overlay__/ext-bin@13";
		ext_bin_14 = "/fragment@3/__overlay__/ext-bin@14";
		ext_bin_15 = "/fragment@3/__overlay__/ext-bin@15";
		ext_bin_16 = "/fragment@3/__overlay__/ext-bin@16";
		ext_bin_17 = "/fragment@3/__overlay__/ext-bin@17";
		ext_bin_18 = "/fragment@3/__overlay__/ext-bin@18";
		tfa98xx_left = "/fragment@7/__overlay__/tfa98xx@34";
		tfa98xx_right = "/fragment@7/__overlay__/tfa98xx@35";
		attn_irq = "/fragment@13/__overlay__/attn-irq";
		attn_input = "/fragment@13/__overlay__/attn-input";
		pm_wrstbi = "/fragment@13/__overlay__/pm-wrstbi";
		key_voldown = "/fragment@13/__overlay__/key-voldown";
		key_volup = "/fragment@13/__overlay__/key-volup";
		dwmmc2_cd_ext_irq = "/fragment@13/__overlay__/dwmmc2_cd_ext_irq";
		dmic1_en = "/fragment@13/__overlay__/dmic1-en";
		dmic1_en_idle = "/fragment@13/__overlay__/dmic1-en-idle";
		dmic2_en = "/fragment@13/__overlay__/dmic2-en";
		dmic2_en_idle = "/fragment@13/__overlay__/dmic2-en-idle";
		smpl_warn = "/fragment@14/__overlay__/smpl-warn";
		__ldo1_reg = "/fragment@15/__overlay__/s2mpb03_pmic@56/regulators/s2mpb03-ldo1";
		__ldo2_reg = "/fragment@15/__overlay__/s2mpb03_pmic@56/regulators/s2mpb03-ldo2";
		__ldo3_reg = "/fragment@15/__overlay__/s2mpb03_pmic@56/regulators/s2mpb03-ldo3";
		__ldo4_reg = "/fragment@15/__overlay__/s2mpb03_pmic@56/regulators/s2mpb03-ldo4";
		__ldo5_reg = "/fragment@15/__overlay__/s2mpb03_pmic@56/regulators/s2mpb03-ldo5";
		__ldo6_reg = "/fragment@15/__overlay__/s2mpb03_pmic@56/regulators/s2mpb03-ldo6";
		__ldo7_reg = "/fragment@15/__overlay__/s2mpb03_pmic@56/regulators/s2mpb03-ldo7";
		drmpanel0 = "/fragment@16/__overlay__/drmpanel";
	};

	__fixups__ {
		gic = "/fragment@modemif/__overlay__/cpif:interrupt-parent:0\0/fragment@modemif/__overlay__/cp_mailbox:interrupt-parent:0\0/fragment@dit/__overlay__/dit:interrupt-parent:0\0/fragment@model/__overlay__/acpm_mfd_bus@11a00000/s2mpu13mfd@1f:interrupt-parent:0\0/fragment@model/__overlay__/gnss_mailbox:interrupt-parent:0\0/fragment@model/__overlay__/gnssif:interrupt-parent:0";
		cp_rmem = "/fragment@modemif/__overlay__/cp_shmem:memory-region:0";
		reserved_memory = "/fragment@0:target:0";
		gpa0 = "/fragment@model/__overlay__/gpio_keys/button@2:gpios:0\0/fragment@1/__overlay__/touchscreen@49:stm,irq_gpio:0";
		gpa1 = "/fragment@model/__overlay__/gpio_keys/button@3:gpios:0";
		gpg0 = "/fragment@model/__overlay__/acpm_mfd_bus@11a00000/s2mpu13mfd@1f:gpios:0";
		gnss_rmem = "/fragment@model/__overlay__/gnssif:memory-region:0";
		abox = "/fragment@model/__overlay__/abox_synchronized_ipc:abox:0\0/fragment@model/__overlay__/sound/usb/cpu:sound-dai:0\0/fragment@model/__overlay__/sound/fwd/cpu:sound-dai:0\0/fragment@3:target:0\0/fragment@11/__overlay__:abox:0";
		abox_effect = "/fragment@model/__overlay__/sound:samsung,aux:0";
		abox_tplg = "/fragment@model/__overlay__/sound:samsung,aux:4";
		abox_rdma_0 = "/fragment@model/__overlay__/sound/rdma0/cpu:sound-dai:0\0/fragment@model/__overlay__/sound/rdma0/platform:sound-dai:0\0/fragment@model/__overlay__/sound/rdma0_be/cpu:sound-dai:0\0/fragment@model/__overlay__/sound/rdma0_be/platform:sound-dai:0";
		abox_rdma_1 = "/fragment@model/__overlay__/sound/rdma1/cpu:sound-dai:0\0/fragment@model/__overlay__/sound/rdma1/platform:sound-dai:0\0/fragment@model/__overlay__/sound/rdma1_be/cpu:sound-dai:0\0/fragment@model/__overlay__/sound/rdma1_be/platform:sound-dai:0";
		abox_rdma_2 = "/fragment@model/__overlay__/sound/rdma2/cpu:sound-dai:0\0/fragment@model/__overlay__/sound/rdma2/platform:sound-dai:0\0/fragment@model/__overlay__/sound/rdma2_be/cpu:sound-dai:0\0/fragment@model/__overlay__/sound/rdma2_be/platform:sound-dai:0";
		abox_rdma_3 = "/fragment@model/__overlay__/sound/rdma3/cpu:sound-dai:0\0/fragment@model/__overlay__/sound/rdma3/platform:sound-dai:0\0/fragment@model/__overlay__/sound/rdma3_be/cpu:sound-dai:0\0/fragment@model/__overlay__/sound/rdma3_be/platform:sound-dai:0";
		abox_rdma_4 = "/fragment@model/__overlay__/sound/rdma4/cpu:sound-dai:0\0/fragment@model/__overlay__/sound/rdma4/platform:sound-dai:0\0/fragment@model/__overlay__/sound/rdma4_be/cpu:sound-dai:0\0/fragment@model/__overlay__/sound/rdma4_be/platform:sound-dai:0";
		abox_rdma_5 = "/fragment@model/__overlay__/sound/rdma5/cpu:sound-dai:0\0/fragment@model/__overlay__/sound/rdma5/platform:sound-dai:0\0/fragment@model/__overlay__/sound/rdma5_be/cpu:sound-dai:0\0/fragment@model/__overlay__/sound/rdma5_be/platform:sound-dai:0";
		abox_rdma_6 = "/fragment@model/__overlay__/sound/rdma6/cpu:sound-dai:0\0/fragment@model/__overlay__/sound/rdma6/platform:sound-dai:0\0/fragment@model/__overlay__/sound/rdma6_be/cpu:sound-dai:0\0/fragment@model/__overlay__/sound/rdma6_be/platform:sound-dai:0";
		abox_rdma_7 = "/fragment@model/__overlay__/sound/rdma7/cpu:sound-dai:0\0/fragment@model/__overlay__/sound/rdma7/platform:sound-dai:0\0/fragment@model/__overlay__/sound/rdma7_be/cpu:sound-dai:0\0/fragment@model/__overlay__/sound/rdma7_be/platform:sound-dai:0";
		abox_rdma_8 = "/fragment@model/__overlay__/sound/rdma8/cpu:sound-dai:0\0/fragment@model/__overlay__/sound/rdma8/platform:sound-dai:0\0/fragment@model/__overlay__/sound/rdma8_be/cpu:sound-dai:0\0/fragment@model/__overlay__/sound/rdma8_be/platform:sound-dai:0";
		abox_rdma_9 = "/fragment@model/__overlay__/sound/rdma9/cpu:sound-dai:0\0/fragment@model/__overlay__/sound/rdma9/platform:sound-dai:0\0/fragment@model/__overlay__/sound/rdma9_be/cpu:sound-dai:0\0/fragment@model/__overlay__/sound/rdma9_be/platform:sound-dai:0";
		abox_rdma_10 = "/fragment@model/__overlay__/sound/rdma10/cpu:sound-dai:0\0/fragment@model/__overlay__/sound/rdma10/platform:sound-dai:0\0/fragment@model/__overlay__/sound/rdma10_be/cpu:sound-dai:0\0/fragment@model/__overlay__/sound/rdma10_be/platform:sound-dai:0";
		abox_rdma_11 = "/fragment@model/__overlay__/sound/rdma11/cpu:sound-dai:0\0/fragment@model/__overlay__/sound/rdma11/platform:sound-dai:0\0/fragment@model/__overlay__/sound/rdma11_be/cpu:sound-dai:0\0/fragment@model/__overlay__/sound/rdma11_be/platform:sound-dai:0";
		abox_wdma_0 = "/fragment@model/__overlay__/sound/wdma0/cpu:sound-dai:0\0/fragment@model/__overlay__/sound/wdma0/platform:sound-dai:0\0/fragment@model/__overlay__/sound/wdma0_be/cpu:sound-dai:0\0/fragment@model/__overlay__/sound/wdma0_be/platform:sound-dai:0";
		abox_wdma_1 = "/fragment@model/__overlay__/sound/wdma1/cpu:sound-dai:0\0/fragment@model/__overlay__/sound/wdma1/platform:sound-dai:0\0/fragment@model/__overlay__/sound/wdma1_be/cpu:sound-dai:0\0/fragment@model/__overlay__/sound/wdma1_be/platform:sound-dai:0";
		abox_wdma_2 = "/fragment@model/__overlay__/sound/wdma2/cpu:sound-dai:0\0/fragment@model/__overlay__/sound/wdma2/platform:sound-dai:0\0/fragment@model/__overlay__/sound/wdma2_be/cpu:sound-dai:0\0/fragment@model/__overlay__/sound/wdma2_be/platform:sound-dai:0";
		abox_wdma_3 = "/fragment@model/__overlay__/sound/wdma3/cpu:sound-dai:0\0/fragment@model/__overlay__/sound/wdma3/platform:sound-dai:0\0/fragment@model/__overlay__/sound/wdma3_be/cpu:sound-dai:0\0/fragment@model/__overlay__/sound/wdma3_be/platform:sound-dai:0";
		abox_wdma_4 = "/fragment@model/__overlay__/sound/wdma4/cpu:sound-dai:0\0/fragment@model/__overlay__/sound/wdma4/platform:sound-dai:0\0/fragment@model/__overlay__/sound/wdma4_be/cpu:sound-dai:0\0/fragment@model/__overlay__/sound/wdma4_be/platform:sound-dai:0";
		abox_wdma_5 = "/fragment@model/__overlay__/sound/wdma5/cpu:sound-dai:0\0/fragment@model/__overlay__/sound/wdma5/platform:sound-dai:0\0/fragment@model/__overlay__/sound/wdma5_be/cpu:sound-dai:0\0/fragment@model/__overlay__/sound/wdma5_be/platform:sound-dai:0";
		abox_wdma_6 = "/fragment@model/__overlay__/sound/wdma6/cpu:sound-dai:0\0/fragment@model/__overlay__/sound/wdma6/platform:sound-dai:0\0/fragment@model/__overlay__/sound/wdma6_be/cpu:sound-dai:0\0/fragment@model/__overlay__/sound/wdma6_be/platform:sound-dai:0";
		abox_wdma_7 = "/fragment@model/__overlay__/sound/wdma7/cpu:sound-dai:0\0/fragment@model/__overlay__/sound/wdma7/platform:sound-dai:0\0/fragment@model/__overlay__/sound/wdma7_be/cpu:sound-dai:0\0/fragment@model/__overlay__/sound/wdma7_be/platform:sound-dai:0";
		abox_wdma_8 = "/fragment@model/__overlay__/sound/wdma8/cpu:sound-dai:0\0/fragment@model/__overlay__/sound/wdma8/platform:sound-dai:0\0/fragment@model/__overlay__/sound/wdma8_be/cpu:sound-dai:0\0/fragment@model/__overlay__/sound/wdma8_be/platform:sound-dai:0";
		abox_wdma_9 = "/fragment@model/__overlay__/sound/wdma9/cpu:sound-dai:0\0/fragment@model/__overlay__/sound/wdma9/platform:sound-dai:0\0/fragment@model/__overlay__/sound/wdma9_be/cpu:sound-dai:0\0/fragment@model/__overlay__/sound/wdma9_be/platform:sound-dai:0";
		abox_wdma_10 = "/fragment@model/__overlay__/sound/wdma10/cpu:sound-dai:0\0/fragment@model/__overlay__/sound/wdma10/platform:sound-dai:0\0/fragment@model/__overlay__/sound/wdma10_be/cpu:sound-dai:0\0/fragment@model/__overlay__/sound/wdma10_be/platform:sound-dai:0";
		abox_wdma_11 = "/fragment@model/__overlay__/sound/wdma11/cpu:sound-dai:0\0/fragment@model/__overlay__/sound/wdma11/platform:sound-dai:0\0/fragment@model/__overlay__/sound/wdma11_be/cpu:sound-dai:0\0/fragment@model/__overlay__/sound/wdma11_be/platform:sound-dai:0";
		vts = "/fragment@model/__overlay__/sound/vts0/cpu:sound-dai:0\0/fragment@model/__overlay__/sound/vts1/cpu:sound-dai:0\0/fragment@6:target:0";
		vts_dma0 = "/fragment@model/__overlay__/sound/vts0/platform:sound-dai:0";
		vts_dma1 = "/fragment@model/__overlay__/sound/vts1/platform:sound-dai:0";
		abox_dual_0 = "/fragment@model/__overlay__/sound/dual0/cpu:sound-dai:0\0/fragment@model/__overlay__/sound/dual0/platform:sound-dai:0";
		abox_dual_1 = "/fragment@model/__overlay__/sound/dual1/cpu:sound-dai:0\0/fragment@model/__overlay__/sound/dual1/platform:sound-dai:0";
		abox_dual_2 = "/fragment@model/__overlay__/sound/dual2/cpu:sound-dai:0\0/fragment@model/__overlay__/sound/dual2/platform:sound-dai:0";
		abox_dual_3 = "/fragment@model/__overlay__/sound/dual3/cpu:sound-dai:0\0/fragment@model/__overlay__/sound/dual3/platform:sound-dai:0";
		abox_dual_4 = "/fragment@model/__overlay__/sound/dual4/cpu:sound-dai:0\0/fragment@model/__overlay__/sound/dual4/platform:sound-dai:0";
		abox_dual_5 = "/fragment@model/__overlay__/sound/dual5/cpu:sound-dai:0\0/fragment@model/__overlay__/sound/dual5/platform:sound-dai:0";
		abox_dual_6 = "/fragment@model/__overlay__/sound/dual6/cpu:sound-dai:0\0/fragment@model/__overlay__/sound/dual6/platform:sound-dai:0";
		abox_dual_7 = "/fragment@model/__overlay__/sound/dual7/cpu:sound-dai:0\0/fragment@model/__overlay__/sound/dual7/platform:sound-dai:0";
		abox_dual_8 = "/fragment@model/__overlay__/sound/dual8/cpu:sound-dai:0\0/fragment@model/__overlay__/sound/dual8/platform:sound-dai:0";
		abox_dual_9 = "/fragment@model/__overlay__/sound/dual9/cpu:sound-dai:0\0/fragment@model/__overlay__/sound/dual9/platform:sound-dai:0";
		abox_dual_10 = "/fragment@model/__overlay__/sound/dual10/cpu:sound-dai:0\0/fragment@model/__overlay__/sound/dual10/platform:sound-dai:0";
		abox_dual_11 = "/fragment@model/__overlay__/sound/dual11/cpu:sound-dai:0\0/fragment@model/__overlay__/sound/dual11/platform:sound-dai:0";
		abox_ddma_0 = "/fragment@model/__overlay__/sound/ddma0/cpu:sound-dai:0\0/fragment@model/__overlay__/sound/ddma0/platform:sound-dai:0";
		abox_ddma_1 = "/fragment@model/__overlay__/sound/ddma1/cpu:sound-dai:0\0/fragment@model/__overlay__/sound/ddma1/platform:sound-dai:0";
		abox_ddma_2 = "/fragment@model/__overlay__/sound/ddma2/cpu:sound-dai:0\0/fragment@model/__overlay__/sound/ddma2/platform:sound-dai:0";
		abox_ddma_3 = "/fragment@model/__overlay__/sound/ddma3/cpu:sound-dai:0\0/fragment@model/__overlay__/sound/ddma3/platform:sound-dai:0";
		abox_ddma_4 = "/fragment@model/__overlay__/sound/ddma4/cpu:sound-dai:0\0/fragment@model/__overlay__/sound/ddma4/platform:sound-dai:0";
		abox_ddma_5 = "/fragment@model/__overlay__/sound/ddma5/cpu:sound-dai:0\0/fragment@model/__overlay__/sound/ddma5/platform:sound-dai:0";
		abox_uaif_0 = "/fragment@model/__overlay__/sound/uaif0/cpu:sound-dai:0";
		abox_uaif_1 = "/fragment@model/__overlay__/sound/uaif1/cpu:sound-dai:0";
		abox_uaif_2 = "/fragment@model/__overlay__/sound/uaif2/cpu:sound-dai:0\0/fragment@4:target:0";
		abox_uaif_3 = "/fragment@model/__overlay__/sound/uaif3/cpu:sound-dai:0\0/fragment@5:target:0";
		abox_uaif_4 = "/fragment@model/__overlay__/sound/uaif4/cpu:sound-dai:0";
		abox_uaif_5 = "/fragment@model/__overlay__/sound/uaif5/cpu:sound-dai:0";
		abox_uaif_6 = "/fragment@model/__overlay__/sound/uaif6/cpu:sound-dai:0";
		vts_s_lif = "/fragment@model/__overlay__/sound/uaif6/codec:sound-dai:0";
		abox_dsif = "/fragment@model/__overlay__/sound/dsif0/cpu:sound-dai:0";
		abox_spdy = "/fragment@model/__overlay__/sound/spdy/cpu:sound-dai:0";
		abox_udma_rd_0 = "/fragment@model/__overlay__/sound/udma_rd0/cpu:sound-dai:0";
		abox_udma_rd_1 = "/fragment@model/__overlay__/sound/udma_rd1/cpu:sound-dai:0";
		abox_udma_wr_0 = "/fragment@model/__overlay__/sound/udma_wr0/cpu:sound-dai:0";
		abox_udma_wr_1 = "/fragment@model/__overlay__/sound/udma_wr1/cpu:sound-dai:0";
		abox_udma_wr_dual_0 = "/fragment@model/__overlay__/sound/udma_wr_dual0/cpu:sound-dai:0";
		abox_udma_wr_dual_1 = "/fragment@model/__overlay__/sound/udma_wr_dual1/cpu:sound-dai:0";
		abox_udma_wr_debug_0 = "/fragment@model/__overlay__/sound/udma_wr_dbg0/cpu:sound-dai:0";
		hsi2c_6 = "/fragment@1:target:0";
		ufs = "/fragment@2:target:0";
		dmic_bus_clk0 = "/fragment@6/__overlay__:pinctrl-0:0\0/fragment@6/__overlay__:pinctrl-3:0";
		dmic_pdm0_bus = "/fragment@6/__overlay__:pinctrl-0:4";
		dmic_bus_clk2 = "/fragment@6/__overlay__:pinctrl-1:0\0/fragment@6/__overlay__:pinctrl-2:0\0/fragment@6/__overlay__:pinctrl-5:0";
		dmic_pdm2_bus = "/fragment@6/__overlay__:pinctrl-1:4\0/fragment@6/__overlay__:pinctrl-2:4";
		amic_pdm0_bus = "/fragment@6/__overlay__:pinctrl-3:4";
		dmic_bus_clk1 = "/fragment@6/__overlay__:pinctrl-4:0";
		amic_pdm1_bus = "/fragment@6/__overlay__:pinctrl-4:4";
		amic_pdm2_bus = "/fragment@6/__overlay__:pinctrl-5:4";
		dmic_bus_clk0_idle = "/fragment@6/__overlay__:pinctrl-6:0";
		dmic_pdm0_idle = "/fragment@6/__overlay__:pinctrl-6:4";
		dmic_bus_clk2_idle = "/fragment@6/__overlay__:pinctrl-7:0\0/fragment@6/__overlay__:pinctrl-8:0";
		dmic_pdm2_idle = "/fragment@6/__overlay__:pinctrl-7:4\0/fragment@6/__overlay__:pinctrl-8:4";
		hsi2c_7 = "/fragment@7:target:0";
		chosen = "/fragment@8:target:0";
		serial_0 = "/fragment@9:target:0\0/fragment@18:target:0";
		udc = "/fragment@10:target:0";
		usbdrd_dwc3 = "/fragment@11:target:0";
		usbdrd_phy0 = "/fragment@12:target:0";
		pinctrl_0 = "/fragment@13:target:0";
		pinctrl_6 = "/fragment@14:target:0";
		hsi2c_25 = "/fragment@15:target:0";
		drmdsim_0 = "/fragment@16:target:0";
		gpc7 = "/fragment@16/__overlay__/drmpanel:reset-gpios:0";
		dwmmc_2 = "/fragment@17:target:0";
		sd2_clk = "/fragment@17/__overlay__:pinctrl-0:0";
		sd2_cmd = "/fragment@17/__overlay__:pinctrl-0:4";
		sd2_bus1 = "/fragment@17/__overlay__:pinctrl-0:8";
		sd2_bus4 = "/fragment@17/__overlay__:pinctrl-0:12";
		sd2_clk_fast_slew_rate_1x = "/fragment@17/__overlay__:pinctrl-1:0";
		sd2_clk_fast_slew_rate_2x = "/fragment@17/__overlay__:pinctrl-2:0";
		sd2_clk_fast_slew_rate_3x = "/fragment@17/__overlay__:pinctrl-3:0";
		sd2_clk_fast_slew_rate_4x = "/fragment@17/__overlay__:pinctrl-4:0";
		sd2_clk_fast_slew_rate_5x = "/fragment@17/__overlay__:pinctrl-5:0";
		sd2_clk_fast_slew_rate_6x = "/fragment@17/__overlay__:pinctrl-6:0";
		gpc0 = "/fragment@17/__overlay__:card-detect:0";
	};

	__local_fixups__ {

		fragment@modemif {

			__overlay__ {

				cp_shmem {
					memory-region = <0x04>;
				};
			};
		};

		fragment@model {

			__overlay__ {

				gpio_keys {
					pinctrl-0 = <0x00 0x04>;
				};

				acpm_mfd_bus@11a00000 {

					s2mpu13mfd@1f {
						pinctrl-0 = <0x00 0x04>;
					};
				};

				gnssif {
					mbox_info = <0x00>;
				};

				sound {
					samsung,codec = <0x00 0x04>;

					uaif1 {

						codec {
							sound-dai = <0x00 0x08>;
						};
					};
				};
			};
		};

		fragment@1 {

			__overlay__ {

				touchscreen@49 {
					pinctrl-0 = <0x00>;
					dvdd-supply = <0x00>;
					avdd-supply = <0x00>;
				};
			};
		};

		fragment@2 {

			__overlay__ {
				vcc-supply = <0x00>;
				vccq2-supply = <0x00>;
			};
		};

		fragment@6 {

			__overlay__ {
				pinctrl-0 = <0x08>;
				pinctrl-1 = <0x08>;
				pinctrl-6 = <0x08>;
				pinctrl-7 = <0x08>;
			};
		};

		fragment@11 {

			__overlay__ {
				vdd33_usb-supply = <0x00>;
			};
		};

		fragment@12 {

			__overlay__ {
				hs_tune_param = <0x00>;
				vdd33_usb-supply = <0x00>;
			};
		};

		fragment@17 {

			__overlay__ {
				pinctrl-0 = <0x10>;
			};
		};
	};
};
